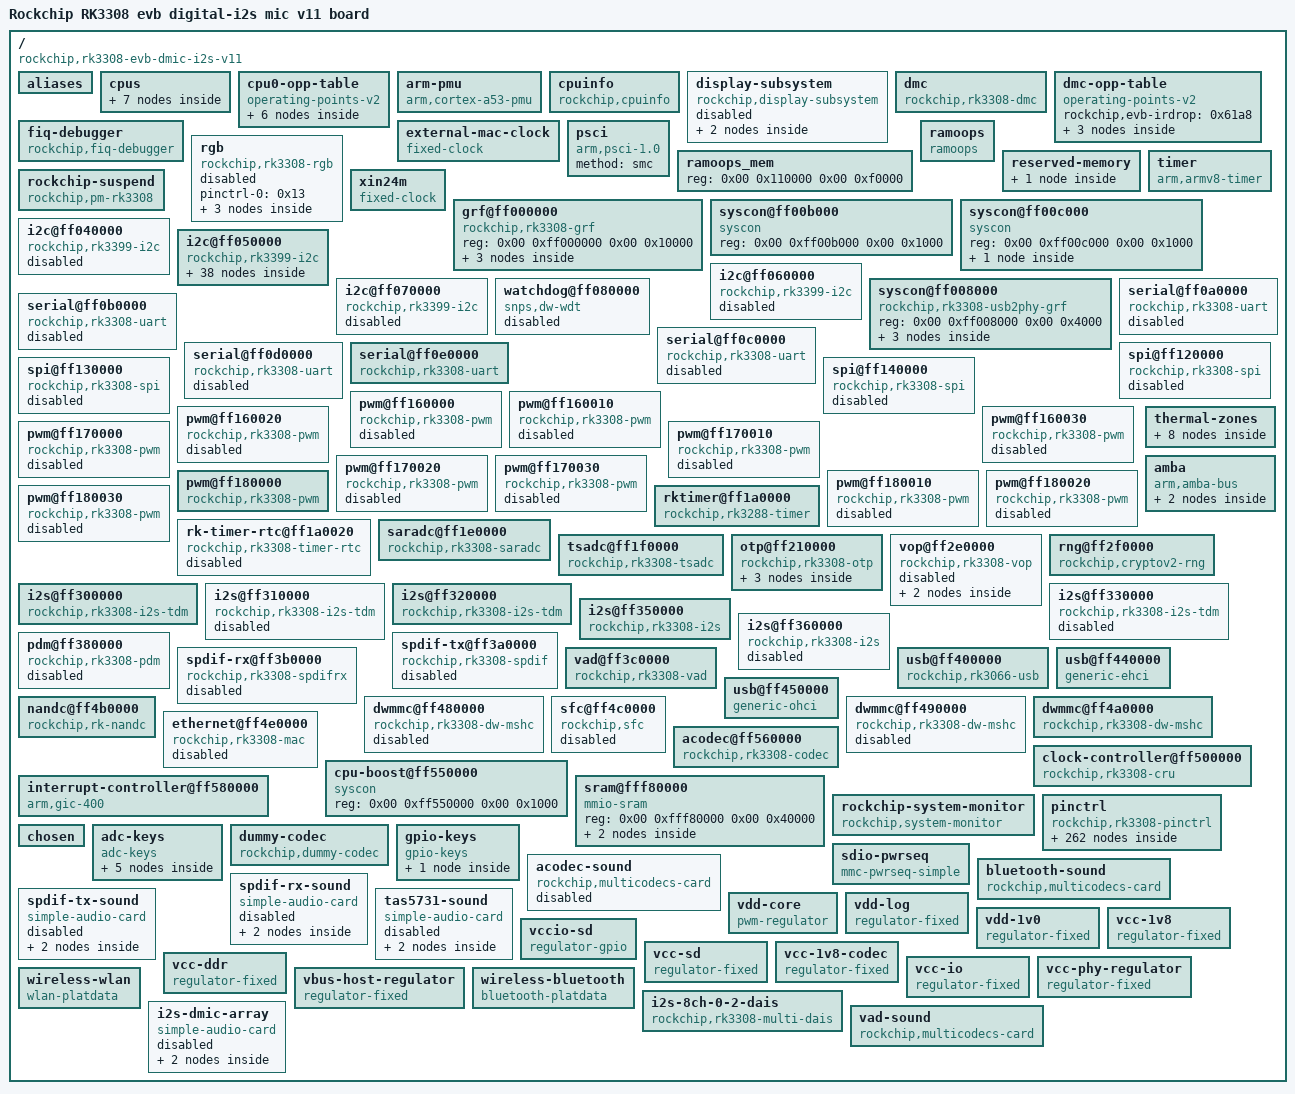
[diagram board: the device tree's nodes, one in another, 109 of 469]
/dts-v1/;

/ {
	compatible = "rockchip,rk3308-evb-dmic-i2s-v11\0rockchip,rk3308";
	interrupt-parent = <0x01>;
	#address-cells = <0x02>;
	#size-cells = <0x02>;
	model = "Rockchip RK3308 evb digital-i2s mic v11 board";

	aliases {
		ethernet0 = "/ethernet@ff4e0000";
		i2c0 = "/i2c@ff040000";
		i2c1 = "/i2c@ff050000";
		i2c2 = "/i2c@ff060000";
		i2c3 = "/i2c@ff070000";
		serial0 = "/serial@ff0a0000";
		serial1 = "/serial@ff0b0000";
		serial2 = "/serial@ff0c0000";
		serial3 = "/serial@ff0d0000";
		serial4 = "/serial@ff0e0000";
		spi0 = "/spi@ff120000";
		spi1 = "/spi@ff130000";
		spi2 = "/spi@ff140000";
	};

	cpus {
		#address-cells = <0x02>;
		#size-cells = <0x00>;

		cpu@0 {
			device_type = "cpu";
			compatible = "arm,cortex-a35\0arm,armv8";
			reg = <0x00 0x00>;
			enable-method = "psci";
			clocks = <0x02 0x05>;
			#cooling-cells = <0x02>;
			dynamic-power-coefficient = <0x5a>;
			operating-points-v2 = <0x03>;
			cpu-idle-states = <0x04>;
			next-level-cache = <0x05>;
			cpu-supply = <0x06>;
			phandle = <0x08>;
		};

		cpu@1 {
			device_type = "cpu";
			compatible = "arm,cortex-a35\0arm,armv8";
			reg = <0x00 0x01>;
			enable-method = "psci";
			operating-points-v2 = <0x03>;
			cpu-idle-states = <0x04>;
			next-level-cache = <0x05>;
			phandle = <0x09>;
		};

		cpu@2 {
			device_type = "cpu";
			compatible = "arm,cortex-a35\0arm,armv8";
			reg = <0x00 0x02>;
			enable-method = "psci";
			operating-points-v2 = <0x03>;
			cpu-idle-states = <0x04>;
			next-level-cache = <0x05>;
			phandle = <0x0a>;
		};

		cpu@3 {
			device_type = "cpu";
			compatible = "arm,cortex-a35\0arm,armv8";
			reg = <0x00 0x03>;
			enable-method = "psci";
			operating-points-v2 = <0x03>;
			cpu-idle-states = <0x04>;
			next-level-cache = <0x05>;
			phandle = <0x0b>;
		};

		idle-states {
			entry-method = "psci";

			cpu-sleep {
				compatible = "arm,idle-state";
				local-timer-stop;
				arm,psci-suspend-param = <0x10000>;
				entry-latency-us = <0x78>;
				exit-latency-us = <0xfa>;
				min-residency-us = <0x384>;
				phandle = <0x04>;
			};
		};

		l2-cache {
			compatible = "cache";
			phandle = <0x05>;
		};
	};

	cpu0-opp-table {
		compatible = "operating-points-v2";
		opp-shared;
		rockchip,temp-hysteresis = <0x1388>;
		rockchip,low-temp = <0x00>;
		rockchip,low-temp-min-volt = <0xf4240>;
		rockchip,max-volt = <0x147260>;
		rockchip,low-temp-adjust-volt = <0x00 0x510 0xc350>;
		rockchip,evb-irdrop = <0x61a8>;
		nvmem-cells = <0x07>;
		nvmem-cell-names = "leakage";
		rockchip,pvtm-voltage-sel = <0x00 0xd2f0 0x00 0xd2f1 0xdac0 0x01 0xdac1 0xe484 0x02 0xe485 0xee48 0x03 0xee49 0xf80c 0x04 0xf80d 0x1869f 0x05>;
		rockchip,pvtm-freq = <0x639c0>;
		rockchip,pvtm-volt = <0xfa3e8>;
		rockchip,pvtm-ch = <0x00 0x00>;
		rockchip,pvtm-sample-time = <0x3e8>;
		rockchip,pvtm-number = <0x0a>;
		rockchip,pvtm-error = <0x3e8>;
		rockchip,pvtm-ref-temp = <0x23>;
		rockchip,pvtm-temp-prop = <0xfffffff1 0xffffffdb>;
		rockchip,thermal-zone = "soc-thermal";
		phandle = <0x03>;

		opp-408000000 {
			opp-hz = <0x00 0x18519600>;
			opp-microvolt = <0xe7ef0 0xe7ef0 0x147260>;
			clock-latency-ns = <0x9c40>;
			opp-suspend;
		};

		opp-600000000 {
			opp-hz = <0x00 0x23c34600>;
			opp-microvolt = <0xe7ef0 0xe7ef0 0x147260>;
			clock-latency-ns = <0x9c40>;
		};

		opp-816000000 {
			opp-hz = <0x00 0x30a32c00>;
			opp-microvolt = <0xfa3e8 0xfa3e8 0x147260>;
			opp-microvolt-L0 = <0xfa3e8 0xfa3e8 0x147260>;
			opp-microvolt-L1 = <0xfa3e8 0xfa3e8 0x147260>;
			opp-microvolt-L2 = <0xfa3e8 0xfa3e8 0x147260>;
			opp-microvolt-L3 = <0xf4240 0xf4240 0x147260>;
			opp-microvolt-L4 = <0xee098 0xee098 0x147260>;
			opp-microvolt-L5 = <0xe7ef0 0xe7ef0 0x147260>;
			clock-latency-ns = <0x9c40>;
		};

		opp-1008000000 {
			opp-hz = <0x00 0x3c14dc00>;
			opp-microvolt = <0x112a88 0x112a88 0x147260>;
			opp-microvolt-L0 = <0x112a88 0x112a88 0x147260>;
			opp-microvolt-L1 = <0x10c8e0 0x10c8e0 0x147260>;
			opp-microvolt-L2 = <0x10c8e0 0x10c8e0 0x147260>;
			opp-microvolt-L3 = <0x106738 0x106738 0x147260>;
			opp-microvolt-L4 = <0x100590 0x100590 0x147260>;
			opp-microvolt-L5 = <0xfa3e8 0xfa3e8 0x147260>;
			clock-latency-ns = <0x9c40>;
		};

		opp-1200000000 {
			opp-hz = <0x00 0x47868c00>;
			opp-microvolt = <0x1312d0 0x1312d0 0x147260>;
			opp-microvolt-L0 = <0x1312d0 0x1312d0 0x147260>;
			opp-microvolt-L1 = <0x12b128 0x12b128 0x147260>;
			opp-microvolt-L2 = <0x124f80 0x124f80 0x147260>;
			opp-microvolt-L3 = <0x11edd8 0x11edd8 0x147260>;
			opp-microvolt-L4 = <0x118c30 0x118c30 0x147260>;
			opp-microvolt-L5 = <0x112a88 0x112a88 0x147260>;
			clock-latency-ns = <0x9c40>;
			status = "okay";
		};

		opp-1296000000 {
			opp-hz = <0x00 0x4d3f6400>;
			opp-microvolt = <0x13d620 0x13d620 0x147260>;
			opp-microvolt-L0 = <0x13d620 0x13d620 0x147260>;
			opp-microvolt-L1 = <0x137478 0x137478 0x147260>;
			opp-microvolt-L2 = <0x1312d0 0x1312d0 0x147260>;
			opp-microvolt-L3 = <0x12b128 0x12b128 0x147260>;
			opp-microvolt-L4 = <0x124f80 0x124f80 0x147260>;
			opp-microvolt-L5 = <0x11edd8 0x11edd8 0x147260>;
			clock-latency-ns = <0x9c40>;
			status = "okay";
		};
	};

	arm-pmu {
		compatible = "arm,cortex-a53-pmu";
		interrupts = <0x00 0x53 0x04 0x00 0x54 0x04 0x00 0x55 0x04 0x00 0x56 0x04>;
		interrupt-affinity = <0x08 0x09 0x0a 0x0b>;
	};

	cpuinfo {
		compatible = "rockchip,cpuinfo";
		nvmem-cells = <0x0c>;
		nvmem-cell-names = "id";
	};

	display-subsystem {
		compatible = "rockchip,display-subsystem";
		ports = <0x0d>;
		logo-memory-region = <0x0e>;
		status = "disabled";
		phandle = <0x9f>;

		route {

			route-rgb {
				status = "disabled";
				logo,uboot = "logo.bmp";
				logo,mode = "center";
				charge_logo,mode = "center";
				connect = <0x0f>;
				phandle = <0xa0>;
			};
		};
	};

	dmc {
		compatible = "rockchip,rk3308-dmc";
		clocks = <0x02 0x46>;
		clock-names = "dmc_clk";
		operating-points-v2 = <0x10>;
		status = "okay";
		center-supply = <0x11>;
		phandle = <0xa1>;
	};

	dmc-opp-table {
		compatible = "operating-points-v2";
		rockchip,evb-irdrop = <0x61a8>;
		phandle = <0x10>;

		opp-394000000 {
			opp-hz = <0x00 0x177bf680>;
			opp-microvolt = <0xe7ef0>;
		};

		opp-452000000 {
			opp-hz = <0x00 0x1af0f900>;
			opp-microvolt = <0xee098>;
		};

		opp-590000000 {
			opp-hz = <0x00 0x232aaf80>;
			opp-microvolt = <0xf4240>;
		};
	};

	fiq-debugger {
		compatible = "rockchip,fiq-debugger";
		rockchip,serial-id = <0x02>;
		rockchip,wake-irq = <0x00>;
		rockchip,irq-mode-enable = <0x00>;
		rockchip,baudrate = <0x16e360>;
		interrupts = <0x00 0x74 0x04>;
		status = "okay";
		phandle = <0xa2>;
	};

	external-mac-clock {
		compatible = "fixed-clock";
		clock-frequency = <0x2faf080>;
		clock-output-names = "mac_clkin";
		#clock-cells = <0x00>;
		phandle = <0x7e>;
	};

	psci {
		compatible = "arm,psci-1.0";
		method = "smc";
	};

	ramoops_mem {
		reg = <0x00 0x110000 0x00 0xf0000>;
		reg-names = "ramoops_mem";
		phandle = <0x12>;
	};

	ramoops {
		compatible = "ramoops";
		record-size = <0x00 0x30000>;
		console-size = <0x00 0xc0000>;
		ftrace-size = <0x00 0x00>;
		pmsg-size = <0x00 0x00>;
		memory-region = <0x12>;
		phandle = <0xa3>;
	};

	rgb {
		compatible = "rockchip,rk3308-rgb";
		status = "disabled";
		pinctrl-names = "default";
		pinctrl-0 = <0x13>;
		phandle = <0xa4>;

		ports {
			#address-cells = <0x01>;
			#size-cells = <0x00>;

			port@0 {
				reg = <0x00>;
				#address-cells = <0x01>;
				#size-cells = <0x00>;

				endpoint@0 {
					reg = <0x00>;
					remote-endpoint = <0x0f>;
					phandle = <0x52>;
				};
			};
		};
	};

	reserved-memory {
		#address-cells = <0x02>;
		#size-cells = <0x02>;
		ranges;

		drm-logo@00000000 {
			compatible = "rockchip,drm-logo";
			reg = <0x00 0x00 0x00 0x00>;
			phandle = <0x0e>;
		};
	};

	rockchip-suspend {
		compatible = "rockchip,pm-rk3308";
		status = "okay";
		rockchip,sleep-mode-config = <0x8000008>;
		rockchip,wakeup-config = <0x40000>;
		rockchip,pwm-regulator-config = <0x04>;
		phandle = <0xa5>;
	};

	timer {
		compatible = "arm,armv8-timer";
		interrupts = <0x01 0x0d 0xf04 0x01 0x0e 0xf04 0x01 0x0b 0xf04 0x01 0x0a 0xf04>;
	};

	xin24m {
		compatible = "fixed-clock";
		#clock-cells = <0x00>;
		clock-frequency = <0x16e3600>;
		clock-output-names = "xin24m";
		phandle = <0xa6>;
	};

	grf@ff000000 {
		compatible = "rockchip,rk3308-grf\0syscon\0simple-mfd";
		reg = <0x00 0xff000000 0x00 0x10000>;
		phandle = <0x4f>;

		io-domains {
			compatible = "rockchip,rk3308-io-voltage-domain";
			status = "okay";
			vccio0-supply = <0x14>;
			vccio1-supply = <0x14>;
			vccio2-supply = <0x15>;
			vccio3-supply = <0x14>;
			vccio4-supply = <0x15>;
			vccio5-supply = <0x16>;
			phandle = <0xa7>;
		};

		pmu-pvtm {
			compatible = "rockchip,rk3308-pmu-pvtm";
			clocks = <0x02 0x4a>;
			clock-names = "pmu";
			phandle = <0xa8>;
		};

		reboot-mode {
			compatible = "syscon-reboot-mode";
			offset = <0x500>;
			mode-bootloader = <0x5242c301>;
			mode-loader = <0x5242c301>;
			mode-normal = <0x5242c300>;
			mode-recovery = <0x5242c303>;
			mode-fastboot = <0x5242c309>;
			mode-panic = <0x5242c307>;
			mode-watchdog = <0x5242c308>;
		};
	};

	syscon@ff00b000 {
		compatible = "syscon\0simple-mfd";
		reg = <0x00 0xff00b000 0x00 0x1000>;
		#address-cells = <0x01>;
		#size-cells = <0x01>;
		phandle = <0x80>;
	};

	syscon@ff00c000 {
		compatible = "syscon\0simple-mfd";
		reg = <0x00 0xff00c000 0x00 0x1000>;
		#address-cells = <0x01>;
		#size-cells = <0x01>;
		phandle = <0xa9>;

		pvtm {
			compatible = "rockchip,rk3308-pvtm";
			clocks = <0x02 0x10>;
			clock-names = "core";
			phandle = <0xaa>;
		};
	};

	i2c@ff040000 {
		compatible = "rockchip,rk3399-i2c";
		reg = <0x00 0xff040000 0x00 0x1000>;
		clocks = <0x02 0x16 0x02 0xca>;
		clock-names = "i2c\0pclk";
		interrupts = <0x00 0x0b 0x04>;
		pinctrl-names = "default";
		pinctrl-0 = <0x17>;
		#address-cells = <0x01>;
		#size-cells = <0x00>;
		status = "disabled";
		phandle = <0xab>;
	};

	i2c@ff050000 {
		compatible = "rockchip,rk3399-i2c";
		reg = <0x00 0xff050000 0x00 0x1000>;
		clocks = <0x02 0x17 0x02 0xcb>;
		clock-names = "i2c\0pclk";
		interrupts = <0x00 0x0c 0x04>;
		pinctrl-names = "default";
		pinctrl-0 = <0x18>;
		#address-cells = <0x01>;
		#size-cells = <0x00>;
		status = "okay";
		clock-frequency = <0x61a80>;
		phandle = <0xac>;

		tas5731@1a {
			#sound-dai-cells = <0x00>;
			compatible = "ti,tas5731";
			reg = <0x1a>;
			clocks = <0x02 0x51>;
			clock-names = "mclk";
			pinctrl-names = "default";
			pinctrl-0 = <0x19>;
			pdn-gpios = <0x1a 0x05 0x01>;
			reset-gpios = <0x1b 0x01 0x01>;
			phandle = <0x96>;
		};

		led-controller@3c {
			compatible = "issi,is31fl3236";
			reg = <0x3c>;
			#address-cells = <0x01>;
			#size-cells = <0x00>;
			reset-gpios = <0x1a 0x08 0x00>;
			status = "okay";
			phandle = <0xad>;

			led@1 {
				label = "led1";
				reg = <0x01>;
				led-max-microamp = <0x2710>;
				linux,default-trigger = "timer";
				linux,default-trigger-delay-ms = <0x00>;
				linux,blink-delay-on-ms = <0x64>;
				linux,blink-delay-off-ms = <0x4b0>;
				phandle = <0xae>;
			};

			led@2 {
				label = "led2";
				reg = <0x02>;
				led-max-microamp = <0x2710>;
				linux,default-trigger = "timer";
				linux,default-trigger-delay-ms = <0x00>;
				linux,blink-delay-on-ms = <0x64>;
				linux,blink-delay-off-ms = <0x4b0>;
				phandle = <0xaf>;
			};

			led@3 {
				label = "led3";
				reg = <0x03>;
				led-max-microamp = <0x2710>;
				linux,default-trigger = "default-on";
				phandle = <0xb0>;
			};

			led@4 {
				label = "led4";
				reg = <0x04>;
				led-max-microamp = <0x2710>;
				linux,default-trigger = "timer";
				linux,default-trigger-delay-ms = <0x64>;
				linux,blink-delay-on-ms = <0x64>;
				linux,blink-delay-off-ms = <0x4b0>;
				phandle = <0xb1>;
			};

			led@5 {
				label = "led5";
				reg = <0x05>;
				led-max-microamp = <0x2710>;
				linux,default-trigger = "timer";
				linux,default-trigger-delay-ms = <0x64>;
				linux,blink-delay-on-ms = <0x64>;
				linux,blink-delay-off-ms = <0x4b0>;
				phandle = <0xb2>;
			};

			led@6 {
				label = "led6";
				reg = <0x06>;
				led-max-microamp = <0x2710>;
				linux,default-trigger = "default-on";
				phandle = <0xb3>;
			};

			led@7 {
				label = "led7";
				reg = <0x07>;
				led-max-microamp = <0x2710>;
				linux,default-trigger = "timer";
				linux,default-trigger-delay-ms = <0xc8>;
				linux,blink-delay-on-ms = <0x64>;
				linux,blink-delay-off-ms = <0x4b0>;
				phandle = <0xb4>;
			};

			led@8 {
				label = "led8";
				reg = <0x08>;
				led-max-microamp = <0x2710>;
				linux,default-trigger = "timer";
				linux,default-trigger-delay-ms = <0xc8>;
				linux,blink-delay-on-ms = <0x64>;
				linux,blink-delay-off-ms = <0x4b0>;
				phandle = <0xb5>;
			};

			led@9 {
				label = "led9";
				reg = <0x09>;
				led-max-microamp = <0x2710>;
				linux,default-trigger = "default-on";
				phandle = <0xb6>;
			};

			led@10 {
				label = "led10";
				reg = <0x0a>;
				led-max-microamp = <0x2710>;
				linux,default-trigger = "timer";
				linux,default-trigger-delay-ms = <0x12c>;
				linux,blink-delay-on-ms = <0x64>;
				linux,blink-delay-off-ms = <0x4b0>;
				phandle = <0xb7>;
			};

			led@11 {
				label = "led11";
				reg = <0x0b>;
				led-max-microamp = <0x2710>;
				linux,default-trigger = "timer";
				linux,default-trigger-delay-ms = <0x12c>;
				linux,blink-delay-on-ms = <0x64>;
				linux,blink-delay-off-ms = <0x4b0>;
				phandle = <0xb8>;
			};

			led@12 {
				label = "led12";
				reg = <0x0c>;
				led-max-microamp = <0x2710>;
				linux,default-trigger = "default-on";
				phandle = <0xb9>;
			};

			led@13 {
				label = "led13";
				reg = <0x0d>;
				led-max-microamp = <0x2710>;
				linux,default-trigger = "timer";
				linux,default-trigger-delay-ms = <0x190>;
				linux,blink-delay-on-ms = <0x64>;
				linux,blink-delay-off-ms = <0x4b0>;
				phandle = <0xba>;
			};

			led@14 {
				label = "led14";
				reg = <0x0e>;
				led-max-microamp = <0x2710>;
				linux,default-trigger = "timer";
				linux,default-trigger-delay-ms = <0x190>;
				linux,blink-delay-on-ms = <0x64>;
				linux,blink-delay-off-ms = <0x4b0>;
				phandle = <0xbb>;
			};

			led@15 {
				label = "led15";
				reg = <0x0f>;
				led-max-microamp = <0x2710>;
				linux,default-trigger = "default-on";
				phandle = <0xbc>;
			};

			led@16 {
				label = "led16";
				reg = <0x10>;
				led-max-microamp = <0x2710>;
				linux,default-trigger = "timer";
				linux,default-trigger-delay-ms = <0x1f4>;
				linux,blink-delay-on-ms = <0x64>;
				linux,blink-delay-off-ms = <0x4b0>;
				phandle = <0xbd>;
			};

			led@17 {
				label = "led17";
				reg = <0x11>;
				led-max-microamp = <0x2710>;
				linux,default-trigger = "timer";
				linux,default-trigger-delay-ms = <0x1f4>;
				linux,blink-delay-on-ms = <0x64>;
				linux,blink-delay-off-ms = <0x4b0>;
				phandle = <0xbe>;
			};

			led@18 {
				label = "led18";
				reg = <0x12>;
				led-max-microamp = <0x2710>;
				linux,default-trigger = "default-on";
				phandle = <0xbf>;
			};

			led@19 {
				label = "led19";
				reg = <0x13>;
				led-max-microamp = <0x2710>;
				linux,default-trigger = "timer";
				linux,default-trigger-delay-ms = <0x258>;
				linux,blink-delay-on-ms = <0x64>;
				linux,blink-delay-off-ms = <0x4b0>;
				phandle = <0xc0>;
			};

			led@20 {
				label = "led20";
				reg = <0x14>;
				led-max-microamp = <0x2710>;
				linux,default-trigger = "timer";
				linux,default-trigger-delay-ms = <0x258>;
				linux,blink-delay-on-ms = <0x64>;
				linux,blink-delay-off-ms = <0x4b0>;
				phandle = <0xc1>;
			};

			led@21 {
				label = "led21";
				reg = <0x15>;
				led-max-microamp = <0x2710>;
				linux,default-trigger = "default-on";
				phandle = <0xc2>;
			};

			led@22 {
				label = "led22";
				reg = <0x16>;
				led-max-microamp = <0x2710>;
				linux,default-trigger = "timer";
				linux,default-trigger-delay-ms = <0x2bc>;
				linux,blink-delay-on-ms = <0x64>;
				linux,blink-delay-off-ms = <0x4b0>;
				phandle = <0xc3>;
			};

			led@23 {
				label = "led23";
				reg = <0x17>;
				led-max-microamp = <0x2710>;
				linux,default-trigger = "timer";
				linux,default-trigger-delay-ms = <0x2bc>;
				linux,blink-delay-on-ms = <0x64>;
				linux,blink-delay-off-ms = <0x4b0>;
				phandle = <0xc4>;
			};

			led@24 {
				label = "led24";
				reg = <0x18>;
				led-max-microamp = <0x2710>;
				linux,default-trigger = "default-on";
				phandle = <0xc5>;
			};

			led@25 {
				label = "led25";
				reg = <0x19>;
				led-max-microamp = <0x2710>;
				linux,default-trigger = "timer";
				linux,default-trigger-delay-ms = <0x320>;
				linux,blink-delay-on-ms = <0x64>;
				linux,blink-delay-off-ms = <0x4b0>;
				phandle = <0xc6>;
			};

			led@26 {
				label = "led26";
				reg = <0x1a>;
				led-max-microamp = <0x2710>;
				linux,default-trigger = "timer";
				linux,default-trigger-delay-ms = <0x320>;
				linux,blink-delay-on-ms = <0x64>;
				linux,blink-delay-off-ms = <0x4b0>;
				phandle = <0xc7>;
			};

			led@27 {
				label = "led27";
				reg = <0x1b>;
				led-max-microamp = <0x2710>;
				linux,default-trigger = "default-on";
				phandle = <0xc8>;
			};

			led@28 {
				label = "led28";
				reg = <0x1c>;
				led-max-microamp = <0x2710>;
				linux,default-trigger = "timer";
				linux,default-trigger-delay-ms = <0x384>;
				linux,blink-delay-on-ms = <0x64>;
				linux,blink-delay-off-ms = <0x4b0>;
				phandle = <0xc9>;
			};

			led@29 {
				label = "led29";
				reg = <0x1d>;
				led-max-microamp = <0x2710>;
				linux,default-trigger = "timer";
				linux,default-trigger-delay-ms = <0x384>;
				linux,blink-delay-on-ms = <0x64>;
				linux,blink-delay-off-ms = <0x4b0>;
				phandle = <0xca>;
			};

			led@30 {
				label = "led30";
				reg = <0x1e>;
				led-max-microamp = <0x2710>;
				linux,default-trigger = "default-on";
				phandle = <0xcb>;
			};

			led@31 {
				label = "led31";
				reg = <0x1f>;
				led-max-microamp = <0x2710>;
				linux,default-trigger = "timer";
				linux,default-trigger-delay-ms = <0x3e8>;
				linux,blink-delay-on-ms = <0x64>;
				linux,blink-delay-off-ms = <0x4b0>;
				phandle = <0xcc>;
			};

			led@32 {
				label = "led32";
				reg = <0x20>;
				led-max-microamp = <0x2710>;
				linux,default-trigger = "timer";
				linux,default-trigger-delay-ms = <0x3e8>;
				linux,blink-delay-on-ms = <0x64>;
				linux,blink-delay-off-ms = <0x4b0>;
				phandle = <0xcd>;
			};

			led@33 {
				label = "led33";
				reg = <0x21>;
				led-max-microamp = <0x2710>;
				linux,default-trigger = "default-on";
				phandle = <0xce>;
			};

			led@34 {
				label = "led34";
				reg = <0x22>;
				led-max-microamp = <0x2710>;
				linux,default-trigger = "timer";
				linux,default-trigger-delay-ms = <0x44c>;
				linux,blink-delay-on-ms = <0x64>;
				linux,blink-delay-off-ms = <0x4b0>;
				phandle = <0xcf>;
			};

			led@35 {
				label = "led35";
				reg = <0x23>;
				led-max-microamp = <0x2710>;
				linux,default-trigger = "timer";
				linux,default-trigger-delay-ms = <0x44c>;
				linux,blink-delay-on-ms = <0x64>;
				linux,blink-delay-off-ms = <0x4b0>;
				phandle = <0xd0>;
			};

			led@36 {
				label = "led36";
				reg = <0x24>;
				led-max-microamp = <0x2710>;
				linux,default-trigger = "default-on";
				phandle = <0xd1>;
			};
		};
	};

	i2c@ff060000 {
		compatible = "rockchip,rk3399-i2c";
		reg = <0x00 0xff060000 0x00 0x1000>;
		clocks = <0x02 0x18 0x02 0xcc>;
		clock-names = "i2c\0pclk";
		interrupts = <0x00 0x0d 0x04>;
		pinctrl-names = "default";
		pinctrl-0 = <0x1c>;
		#address-cells = <0x01>;
		#size-cells = <0x00>;
		status = "disabled";
		phandle = <0xd2>;
	};

	i2c@ff070000 {
		compatible = "rockchip,rk3399-i2c";
		reg = <0x00 0xff070000 0x00 0x1000>;
		clocks = <0x02 0x19 0x02 0xcd>;
		clock-names = "i2c\0pclk";
		interrupts = <0x00 0x0e 0x04>;
		pinctrl-names = "default";
		pinctrl-0 = <0x1d>;
		#address-cells = <0x01>;
		#size-cells = <0x00>;
		status = "disabled";
		phandle = <0xd3>;
	};

	syscon@ff008000 {
		compatible = "rockchip,rk3308-usb2phy-grf\0syscon\0simple-mfd";
		reg = <0x00 0xff008000 0x00 0x4000>;
		#address-cells = <0x01>;
		#size-cells = <0x01>;
		phandle = <0xd4>;

		usb2-phy@100 {
			compatible = "rockchip,rk3308-usb2phy";
			reg = <0x100 0x10>;
			clocks = <0x02 0x48>;
			clock-names = "phyclk";
			#clock-cells = <0x00>;
			assigned-clocks = <0x02 0x0e>;
			assigned-clock-parents = <0x1e>;
			clock-output-names = "usb480m_phy";
			status = "okay";
			phandle = <0x1e>;

			otg-port {
				#phy-cells = <0x00>;
				interrupts = <0x00 0x43 0x04 0x00 0x44 0x04 0x00 0x45 0x04>;
				interrupt-names = "otg-bvalid\0otg-id\0linestate";
				status = "okay";
				phandle = <0x70>;
			};

			host-port {
				#phy-cells = <0x00>;
				interrupts = <0x00 0x4a 0x04>;
				interrupt-names = "linestate";
				status = "okay";
				phy-supply = <0x1f>;
				phandle = <0x71>;
			};
		};
	};

	watchdog@ff080000 {
		compatible = "snps,dw-wdt";
		reg = <0x00 0xff080000 0x00 0x100>;
		clocks = <0x02 0xd6>;
		interrupts = <0x00 0x0a 0x04>;
		status = "disabled";
		phandle = <0xd5>;
	};

	serial@ff0a0000 {
		compatible = "rockchip,rk3308-uart\0snps,dw-apb-uart";
		reg = <0x00 0xff0a0000 0x00 0x100>;
		interrupts = <0x00 0x12 0x04>;
		clocks = <0x02 0x11 0x02 0xc5>;
		clock-names = "baudclk\0apb_pclk";
		reg-shift = <0x02>;
		reg-io-width = <0x04>;
		dmas = <0x20 0x04 0x20 0x05>;
		dma-names = "tx\0rx";
		pinctrl-names = "default";
		pinctrl-0 = <0x21 0x22 0x23>;
		status = "disabled";
		phandle = <0xd6>;
	};

	serial@ff0b0000 {
		compatible = "rockchip,rk3308-uart\0snps,dw-apb-uart";
		reg = <0x00 0xff0b0000 0x00 0x100>;
		interrupts = <0x00 0x13 0x04>;
		clocks = <0x02 0x12 0x02 0xc6>;
		clock-names = "baudclk\0apb_pclk";
		reg-shift = <0x02>;
		reg-io-width = <0x04>;
		dmas = <0x20 0x06 0x20 0x07>;
		dma-names = "tx\0rx";
		pinctrl-names = "default";
		pinctrl-0 = <0x24 0x25 0x26>;
		status = "disabled";
		phandle = <0xd7>;
	};

	serial@ff0c0000 {
		compatible = "rockchip,rk3308-uart\0snps,dw-apb-uart";
		reg = <0x00 0xff0c0000 0x00 0x100>;
		interrupts = <0x00 0x14 0x04>;
		clocks = <0x02 0x13 0x02 0xc7>;
		clock-names = "baudclk\0apb_pclk";
		reg-shift = <0x02>;
		reg-io-width = <0x04>;
		dmas = <0x20 0x08 0x20 0x09>;
		dma-names = "tx\0rx";
		pinctrl-names = "default";
		pinctrl-0 = <0x27>;
		status = "disabled";
		phandle = <0xd8>;
	};

	serial@ff0d0000 {
		compatible = "rockchip,rk3308-uart\0snps,dw-apb-uart";
		reg = <0x00 0xff0d0000 0x00 0x100>;
		interrupts = <0x00 0x15 0x04>;
		clocks = <0x02 0x14 0x02 0xc8>;
		clock-names = "baudclk\0apb_pclk";
		reg-shift = <0x02>;
		reg-io-width = <0x04>;
		dmas = <0x20 0x0a 0x20 0x0b>;
		dma-names = "tx\0rx";
		pinctrl-names = "default";
		pinctrl-0 = <0x28>;
		status = "disabled";
		phandle = <0xd9>;
	};

	serial@ff0e0000 {
		compatible = "rockchip,rk3308-uart\0snps,dw-apb-uart";
		reg = <0x00 0xff0e0000 0x00 0x100>;
		interrupts = <0x00 0x16 0x04>;
		clocks = <0x02 0x15 0x02 0xc9>;
		clock-names = "baudclk\0apb_pclk";
		reg-shift = <0x02>;
		reg-io-width = <0x04>;
		dmas = <0x29 0x12 0x29 0x13>;
		dma-names = "tx\0rx";
		pinctrl-names = "default";
		pinctrl-0 = <0x2a 0x2b>;
		status = "okay";
		phandle = <0xda>;
	};

	spi@ff120000 {
		compatible = "rockchip,rk3308-spi\0rockchip,rk3066-spi";
		reg = <0x00 0xff120000 0x00 0x1000>;
		interrupts = <0x00 0x0f 0x04>;
		#address-cells = <0x01>;
		#size-cells = <0x00>;
		clocks = <0x02 0x1b 0x02 0xcf>;
		clock-names = "spiclk\0apb_pclk";
		dmas = <0x20 0x00 0x20 0x01>;
		dma-names = "tx\0rx";
		pinctrl-names = "default\0high_speed";
		pinctrl-0 = <0x2c 0x2d 0x2e 0x2f>;
		pinctrl-1 = <0x30 0x2d 0x31 0x32>;
		status = "disabled";
		phandle = <0xdb>;
	};

	spi@ff130000 {
		compatible = "rockchip,rk3308-spi\0rockchip,rk3066-spi";
		reg = <0x00 0xff130000 0x00 0x1000>;
		interrupts = <0x00 0x10 0x04>;
		#address-cells = <0x01>;
		#size-cells = <0x00>;
		clocks = <0x02 0x1c 0x02 0xd0>;
		clock-names = "spiclk\0apb_pclk";
		dmas = <0x20 0x02 0x20 0x03>;
		dma-names = "tx\0rx";
		pinctrl-names = "default\0high_speed";
		pinctrl-0 = <0x33 0x34 0x35 0x36>;
		pinctrl-1 = <0x37 0x34 0x38 0x39>;
		status = "disabled";
		phandle = <0xdc>;
	};

	spi@ff140000 {
		compatible = "rockchip,rk3308-spi\0rockchip,rk3066-spi";
		reg = <0x00 0xff140000 0x00 0x1000>;
		interrupts = <0x00 0x11 0x04>;
		#address-cells = <0x01>;
		#size-cells = <0x00>;
		clocks = <0x02 0x1d 0x02 0xd1>;
		clock-names = "spiclk\0apb_pclk";
		dmas = <0x29 0x10 0x29 0x11>;
		dma-names = "tx\0rx";
		pinctrl-names = "default\0high_speed";
		pinctrl-0 = <0x3a 0x3b 0x3c 0x3d>;
		pinctrl-1 = <0x3e 0x3b 0x3f 0x40>;
		status = "disabled";
		phandle = <0xdd>;
	};

	pwm@ff160000 {
		compatible = "rockchip,rk3308-pwm\0rockchip,rk3328-pwm";
		reg = <0x00 0xff160000 0x00 0x10>;
		#pwm-cells = <0x03>;
		pinctrl-names = "active";
		pinctrl-0 = <0x41>;
		clocks = <0x02 0x79 0x02 0xe8>;
		clock-names = "pwm\0pclk";
		status = "disabled";
		phandle = <0xde>;
	};

	pwm@ff160010 {
		compatible = "rockchip,rk3308-pwm\0rockchip,rk3328-pwm";
		reg = <0x00 0xff160010 0x00 0x10>;
		#pwm-cells = <0x03>;
		pinctrl-names = "active";
		pinctrl-0 = <0x42>;
		clocks = <0x02 0x79 0x02 0xe8>;
		clock-names = "pwm\0pclk";
		status = "disabled";
		phandle = <0xdf>;
	};

	pwm@ff160020 {
		compatible = "rockchip,rk3308-pwm\0rockchip,rk3328-pwm";
		reg = <0x00 0xff160020 0x00 0x10>;
		#pwm-cells = <0x03>;
		pinctrl-names = "active";
		pinctrl-0 = <0x43>;
		clocks = <0x02 0x79 0x02 0xe8>;
		clock-names = "pwm\0pclk";
		status = "disabled";
		phandle = <0xe0>;
	};

	pwm@ff160030 {
		compatible = "rockchip,rk3308-pwm\0rockchip,rk3328-pwm";
		reg = <0x00 0xff160030 0x00 0x10>;
		#pwm-cells = <0x03>;
		pinctrl-names = "active";
		pinctrl-0 = <0x44>;
		clocks = <0x02 0x79 0x02 0xe8>;
		clock-names = "pwm\0pclk";
		status = "disabled";
		phandle = <0xe1>;
	};

	pwm@ff170000 {
		compatible = "rockchip,rk3308-pwm\0rockchip,rk3328-pwm";
		reg = <0x00 0xff170000 0x00 0x10>;
		#pwm-cells = <0x03>;
		pinctrl-names = "active";
		pinctrl-0 = <0x45>;
		clocks = <0x02 0x78 0x02 0xe7>;
		clock-names = "pwm\0pclk";
		status = "disabled";
		phandle = <0xe2>;
	};

	pwm@ff170010 {
		compatible = "rockchip,rk3308-pwm\0rockchip,rk3328-pwm";
		reg = <0x00 0xff170010 0x00 0x10>;
		#pwm-cells = <0x03>;
		pinctrl-names = "active";
		pinctrl-0 = <0x46>;
		clocks = <0x02 0x78 0x02 0xe7>;
		clock-names = "pwm\0pclk";
		status = "disabled";
		phandle = <0xe3>;
	};

	pwm@ff170020 {
		compatible = "rockchip,rk3308-pwm\0rockchip,rk3328-pwm";
		reg = <0x00 0xff170020 0x00 0x10>;
		#pwm-cells = <0x03>;
		pinctrl-names = "active";
		pinctrl-0 = <0x47>;
		clocks = <0x02 0x78 0x02 0xe7>;
		clock-names = "pwm\0pclk";
		status = "disabled";
		phandle = <0xe4>;
	};

	pwm@ff170030 {
		compatible = "rockchip,rk3308-pwm\0rockchip,rk3328-pwm";
		reg = <0x00 0xff170030 0x00 0x10>;
		#pwm-cells = <0x03>;
		pinctrl-names = "active";
		pinctrl-0 = <0x48>;
		clocks = <0x02 0x78 0x02 0xe7>;
		clock-names = "pwm\0pclk";
		status = "disabled";
		phandle = <0xe5>;
	};

	pwm@ff180000 {
		compatible = "rockchip,rk3308-pwm\0rockchip,rk3328-pwm";
		reg = <0x00 0xff180000 0x00 0x10>;
		#pwm-cells = <0x03>;
		pinctrl-names = "active";
		pinctrl-0 = <0x49>;
		clocks = <0x02 0x1a 0x02 0xce>;
		clock-names = "pwm\0pclk";
		status = "okay";
		phandle = <0x97>;
	};

	pwm@ff180010 {
		compatible = "rockchip,rk3308-pwm\0rockchip,rk3328-pwm";
		reg = <0x00 0xff180010 0x00 0x10>;
		#pwm-cells = <0x03>;
		pinctrl-names = "active";
		pinctrl-0 = <0x4a>;
		clocks = <0x02 0x1a 0x02 0xce>;
		clock-names = "pwm\0pclk";
		status = "disabled";
		phandle = <0xe6>;
	};

	pwm@ff180020 {
		compatible = "rockchip,rk3308-pwm\0rockchip,rk3328-pwm";
		reg = <0x00 0xff180020 0x00 0x10>;
		#pwm-cells = <0x03>;
		pinctrl-names = "active";
		pinctrl-0 = <0x4b>;
		clocks = <0x02 0x1a 0x02 0xce>;
		clock-names = "pwm\0pclk";
		status = "disabled";
		phandle = <0xe7>;
	};

	pwm@ff180030 {
		compatible = "rockchip,rk3308-pwm\0rockchip,rk3328-pwm";
		reg = <0x00 0xff180030 0x00 0x10>;
		#pwm-cells = <0x03>;
		pinctrl-names = "active";
		pinctrl-0 = <0x4c>;
		clocks = <0x02 0x1a 0x02 0xce>;
		clock-names = "pwm\0pclk";
		status = "disabled";
		phandle = <0xe8>;
	};

	rktimer@ff1a0000 {
		compatible = "rockchip,rk3288-timer";
		reg = <0x00 0xff1a0000 0x00 0x20>;
		interrupts = <0x00 0x19 0x04>;
		clocks = <0x02 0xd4 0x02 0x1e>;
		clock-names = "pclk\0timer";
		phandle = <0xe9>;
	};

	rk-timer-rtc@ff1a0020 {
		compatible = "rockchip,rk3308-timer-rtc";
		reg = <0x00 0xff1a0020 0x00 0x20>;
		interrupts = <0x00 0x1a 0x04>;
		clocks = <0x02 0xd4 0x02 0x1f>;
		clock-names = "pclk\0timer";
		status = "disabled";
		phandle = <0xea>;
	};

	saradc@ff1e0000 {
		compatible = "rockchip,rk3308-saradc\0rockchip,rk3399-saradc";
		reg = <0x00 0xff1e0000 0x00 0x100>;
		interrupts = <0x00 0x25 0x04>;
		#io-channel-cells = <0x01>;
		clocks = <0x02 0x25 0x02 0xd2>;
		clock-names = "saradc\0apb_pclk";
		resets = <0x02 0x46>;
		reset-names = "saradc-apb";
		status = "okay";
		vref-supply = <0x15>;
		phandle = <0x8c>;
	};

	thermal-zones {
		phandle = <0xeb>;

		soc-thermal {
			polling-delay-passive = <0x14>;
			polling-delay = <0x3e8>;
			sustainable-power = <0x12c>;
			thermal-sensors = <0x4d 0x00>;
			phandle = <0xec>;

			trips {

				trip-point-0 {
					temperature = <0x11170>;
					hysteresis = <0x7d0>;
					type = "passive";
					phandle = <0xed>;
				};

				trip-point-1 {
					temperature = <0x14c08>;
					hysteresis = <0x7d0>;
					type = "passive";
					phandle = <0x4e>;
				};

				soc-crit {
					temperature = <0x1c138>;
					hysteresis = <0x7d0>;
					type = "critical";
					phandle = <0xee>;
				};
			};

			cooling-maps {

				map0 {
					trip = <0x4e>;
					cooling-device = <0x08 0xffffffff 0xffffffff>;
					contribution = <0x1000>;
				};
			};
		};

		logic-thermal {
			polling-delay-passive = <0x64>;
			polling-delay = <0x3e8>;
			thermal-sensors = <0x4d 0x01>;
			phandle = <0xef>;
		};
	};

	tsadc@ff1f0000 {
		compatible = "rockchip,rk3308-tsadc";
		reg = <0x00 0xff1f0000 0x00 0x100>;
		interrupts = <0x00 0x26 0x04>;
		rockchip,grf = <0x4f>;
		clocks = <0x02 0x24 0x02 0xd3>;
		clock-names = "tsadc\0apb_pclk";
		assigned-clocks = <0x02 0x24>;
		assigned-clock-rates = <0xc350>;
		resets = <0x02 0x48>;
		reset-names = "tsadc-apb";
		pinctrl-names = "gpio\0otpout";
		pinctrl-0 = <0x50>;
		pinctrl-1 = <0x51>;
		#thermal-sensor-cells = <0x01>;
		rockchip,hw-tshut-temp = <0x1d4c0>;
		status = "okay";
		rockchip,hw-tshut-mode = <0x00>;
		rockchip,hw-tshut-polarity = <0x01>;
		phandle = <0x4d>;
	};

	otp@ff210000 {
		compatible = "rockchip,rk3308-otp";
		reg = <0x00 0xff210000 0x00 0x4000>;
		#address-cells = <0x01>;
		#size-cells = <0x01>;
		clocks = <0x02 0x27 0x02 0xd5 0x02 0xe5>;
		clock-names = "clk_otp\0pclk_otp\0pclk_otp_phy";
		resets = <0x02 0x54>;
		reset-names = "otp_phy";
		phandle = <0xf0>;

		id@7 {
			reg = <0x07 0x10>;
			phandle = <0x0c>;
		};

		cpu-leakage@17 {
			reg = <0x17 0x01>;
			phandle = <0x07>;
		};

		logic-leakage@18 {
			reg = <0x18 0x01>;
			phandle = <0xf1>;
		};
	};

	amba {
		compatible = "arm,amba-bus";
		#address-cells = <0x02>;
		#size-cells = <0x02>;
		ranges;

		dma-controller@ff2c0000 {
			compatible = "arm,pl330\0arm,primecell";
			reg = <0x00 0xff2c0000 0x00 0x4000>;
			interrupts = <0x00 0x00 0x04 0x00 0x01 0x04>;
			#dma-cells = <0x01>;
			clocks = <0x02 0x8a>;
			clock-names = "apb_pclk";
			peripherals-req-type-burst;
			phandle = <0x20>;
		};

		dma-controller@ff2d0000 {
			compatible = "arm,pl330\0arm,primecell";
			reg = <0x00 0xff2d0000 0x00 0x4000>;
			interrupts = <0x00 0x02 0x04 0x00 0x03 0x04>;
			#dma-cells = <0x01>;
			clocks = <0x02 0x8b>;
			clock-names = "apb_pclk";
			peripherals-req-type-burst;
			phandle = <0x29>;
		};
	};

	vop@ff2e0000 {
		compatible = "rockchip,rk3308-vop";
		reg = <0x00 0xff2e0000 0x00 0x1fc 0x00 0xff2e0a00 0x00 0x400>;
		reg-names = "regs\0gamma_lut";
		interrupts = <0x00 0x2e 0x04>;
		clocks = <0x02 0x88 0x02 0x7d 0x02 0xac>;
		clock-names = "aclk_vop\0dclk_vop\0hclk_vop";
		status = "disabled";
		phandle = <0xf2>;

		port {
			#address-cells = <0x01>;
			#size-cells = <0x00>;
			phandle = <0x0d>;

			endpoint@0 {
				reg = <0x00>;
				remote-endpoint = <0x52>;
				phandle = <0x0f>;
			};
		};
	};

	rng@ff2f0000 {
		compatible = "rockchip,cryptov2-rng";
		reg = <0x00 0xff2f0000 0x00 0x4000>;
		clocks = <0x02 0x29 0x02 0x2a 0x02 0x87 0x02 0xab>;
		clock-names = "clk_crypto\0clk_crypto_apk\0aclk_crypto\0hclk_crypto";
		assigned-clocks = <0x02 0x29 0x02 0x2a 0x02 0x87 0x02 0xab>;
		assigned-clock-rates = <0x8f0d180 0x8f0d180 0xbebc200 0x5f5e100>;
		resets = <0x02 0x24>;
		reset-names = "reset";
		status = "okay";
		phandle = <0xf3>;
	};

	i2s@ff300000 {
		compatible = "rockchip,rk3308-i2s-tdm";
		reg = <0x00 0xff300000 0x00 0x1000>;
		interrupts = <0x00 0x30 0x04>;
		clocks = <0x02 0x4c 0x02 0x4e 0x02 0xa4 0x02 0x6e 0x02 0x6f 0x02 0x03 0x02 0x04>;
		clock-names = "mclk_tx\0mclk_rx\0hclk\0mclk_tx_src\0mclk_rx_src\0mclk_root0\0mclk_root1";
		dmas = <0x29 0x00 0x29 0x01>;
		dma-names = "tx\0rx";
		resets = <0x02 0x89 0x02 0x8a>;
		reset-names = "tx-m\0rx-m";
		rockchip,cru = <0x02>;
		rockchip,grf = <0x4f>;
		rockchip,mclk-calibrate;
		pinctrl-names = "default";
		pinctrl-0 = <0x53 0x54 0x55 0x56 0x57 0x58 0x59 0x5a 0x5b 0x5c 0x5d 0x5e 0x5f>;
		status = "okay";
		rockchip,no-dmaengine;
		#sound-dai-cells = <0x00>;
		phandle = <0x6f>;
	};

	i2s@ff310000 {
		compatible = "rockchip,rk3308-i2s-tdm";
		reg = <0x00 0xff310000 0x00 0x1000>;
		interrupts = <0x00 0x31 0x04>;
		clocks = <0x02 0x50 0x02 0x52 0x02 0xa5 0x02 0x70 0x02 0x71 0x02 0x03 0x02 0x04>;
		clock-names = "mclk_tx\0mclk_rx\0hclk\0mclk_tx_src\0mclk_rx_src\0mclk_root0\0mclk_root1";
		dmas = <0x29 0x02 0x29 0x03>;
		dma-names = "tx\0rx";
		resets = <0x02 0x8c 0x02 0x8d>;
		reset-names = "tx-m\0rx-m";
		rockchip,cru = <0x02>;
		rockchip,grf = <0x4f>;
		rockchip,mclk-calibrate;
		rockchip,io-multiplex;
		status = "disabled";
		#sound-dai-cells = <0x00>;
		pinctrl-names = "default";
		pinctrl-0 = <0x60 0x61 0x62 0x19>;
		phandle = <0x95>;
	};

	i2s@ff320000 {
		compatible = "rockchip,rk3308-i2s-tdm";
		reg = <0x00 0xff320000 0x00 0x1000>;
		interrupts = <0x00 0x32 0x04>;
		clocks = <0x02 0x54 0x02 0x56 0x02 0xa6 0x02 0x72 0x02 0x73 0x02 0x03 0x02 0x04>;
		clock-names = "mclk_tx\0mclk_rx\0hclk\0mclk_tx_src\0mclk_rx_src\0mclk_root0\0mclk_root1";
		dmas = <0x29 0x04 0x29 0x05>;
		dma-names = "tx\0rx";
		resets = <0x02 0x8f 0x02 0x90>;
		reset-names = "tx-m\0rx-m";
		rockchip,cru = <0x02>;
		rockchip,grf = <0x4f>;
		rockchip,mclk-calibrate;
		status = "okay";
		rockchip,no-dmaengine;
		#sound-dai-cells = <0x00>;
		phandle = <0x8f>;
	};

	i2s@ff330000 {
		compatible = "rockchip,rk3308-i2s-tdm";
		reg = <0x00 0xff330000 0x00 0x1000>;
		interrupts = <0x00 0x33 0x04>;
		clocks = <0x02 0x58 0x02 0x5a 0x02 0xa7 0x02 0x74 0x02 0x75 0x02 0x03 0x02 0x04>;
		clock-names = "mclk_tx\0mclk_rx\0hclk\0mclk_tx_src\0mclk_rx_src\0mclk_root0\0mclk_root1";
		dmas = <0x29 0x07>;
		dma-names = "rx";
		resets = <0x02 0x92 0x02 0x93>;
		reset-names = "tx-m\0rx-m";
		rockchip,cru = <0x02>;
		rockchip,grf = <0x4f>;
		rockchip,mclk-calibrate;
		status = "disabled";
		phandle = <0xf4>;
	};

	i2s@ff350000 {
		compatible = "rockchip,rk3308-i2s\0rockchip,rk3066-i2s";
		reg = <0x00 0xff350000 0x00 0x1000>;
		interrupts = <0x00 0x34 0x04>;
		clocks = <0x02 0x5c 0x02 0xa8>;
		clock-names = "i2s_clk\0i2s_hclk";
		dmas = <0x29 0x08 0x29 0x09>;
		dma-names = "tx\0rx";
		resets = <0x02 0x95 0x02 0x94>;
		reset-names = "reset-m\0reset-h";
		pinctrl-names = "default";
		pinctrl-0 = <0x63 0x64 0x65 0x66>;
		status = "okay";
		#sound-dai-cells = <0x00>;
		rockchip,clk-trcm = <0x01>;
		phandle = <0x91>;
	};

	i2s@ff360000 {
		compatible = "rockchip,rk3308-i2s\0rockchip,rk3066-i2s";
		reg = <0x00 0xff360000 0x00 0x1000>;
		interrupts = <0x00 0x35 0x04>;
		clocks = <0x02 0x5e 0x02 0xa9>;
		clock-names = "i2s_clk\0i2s_hclk";
		dmas = <0x29 0x0b>;
		dma-names = "rx";
		resets = <0x02 0x97 0x02 0x96>;
		reset-names = "reset-m\0reset-h";
		status = "disabled";
		phandle = <0xf5>;
	};

	pdm@ff380000 {
		compatible = "rockchip,rk3308-pdm\0rockchip,pdm";
		reg = <0x00 0xff380000 0x00 0x1000>;
		clocks = <0x02 0x4b 0x02 0xa1>;
		clock-names = "pdm_clk\0pdm_hclk";
		dmas = <0x29 0x0c>;
		dma-names = "rx";
		resets = <0x02 0x83>;
		reset-names = "pdm-m";
		pinctrl-names = "default";
		pinctrl-0 = <0x67 0x68 0x69 0x6a 0x6b>;
		status = "disabled";
		phandle = <0xf6>;
	};

	spdif-tx@ff3a0000 {
		compatible = "rockchip,rk3308-spdif\0rockchip,rk3328-spdif";
		reg = <0x00 0xff3a0000 0x00 0x1000>;
		interrupts = <0x00 0x37 0x04>;
		clocks = <0x02 0x62 0x02 0xa2>;
		clock-names = "mclk\0hclk";
		dmas = <0x29 0x0d>;
		dma-names = "tx";
		pinctrl-names = "default";
		pinctrl-0 = <0x6c>;
		status = "disabled";
		phandle = <0x94>;
	};

	spdif-rx@ff3b0000 {
		compatible = "rockchip,rk3308-spdifrx";
		reg = <0x00 0xff3b0000 0x00 0x1000>;
		interrupts = <0x00 0x38 0x04>;
		clocks = <0x02 0x65 0x02 0xa3>;
		clock-names = "mclk\0hclk";
		dmas = <0x29 0x0e>;
		dma-names = "rx";
		resets = <0x02 0x87>;
		reset-names = "spdifrx-m";
		pinctrl-names = "default";
		pinctrl-0 = <0x6d>;
		status = "disabled";
		phandle = <0x93>;
	};

	vad@ff3c0000 {
		compatible = "rockchip,rk3308-vad";
		reg = <0x00 0xff3c0000 0x00 0x10000>;
		reg-names = "vad";
		clocks = <0x02 0xaa>;
		clock-names = "hclk";
		interrupts = <0x00 0x39 0x04>;
		rockchip,audio-sram = <0x6e>;
		rockchip,audio-src = <0x6f>;
		rockchip,det-channel = <0x00>;
		rockchip,mode = <0x01>;
		status = "okay";
		rockchip,buffer-time-ms = <0xc8>;
		#sound-dai-cells = <0x00>;
		phandle = <0x9e>;
	};

	usb@ff400000 {
		compatible = "rockchip,rk3066-usb\0snps,dwc2";
		reg = <0x00 0xff400000 0x00 0x40000>;
		interrupts = <0x00 0x42 0x04>;
		clocks = <0x02 0x9e>;
		clock-names = "otg";
		dr_mode = "otg";
		g-np-tx-fifo-size = <0x10>;
		g-rx-fifo-size = <0x118>;
		g-tx-fifo-size = <0x100 0x80 0x80 0x40 0x20 0x10>;
		g-use-dma;
		phys = <0x70>;
		phy-names = "usb2-phy";
		status = "okay";
		phandle = <0xf7>;
	};

	usb@ff440000 {
		compatible = "generic-ehci";
		reg = <0x00 0xff440000 0x00 0x10000>;
		interrupts = <0x00 0x47 0x04>;
		clocks = <0x02 0x9f 0x02 0xa0 0x1e>;
		clock-names = "usbhost\0arbiter\0utmi";
		phys = <0x71>;
		phy-names = "usb";
		status = "okay";
		phandle = <0xf8>;
	};

	usb@ff450000 {
		compatible = "generic-ohci";
		reg = <0x00 0xff450000 0x00 0x10000>;
		interrupts = <0x00 0x48 0x04>;
		clocks = <0x02 0x9f 0x02 0xa0 0x1e>;
		clock-names = "usbhost\0arbiter\0utmi";
		phys = <0x71>;
		phy-names = "usb";
		status = "okay";
		phandle = <0xf9>;
	};

	dwmmc@ff480000 {
		compatible = "rockchip,rk3308-dw-mshc\0rockchip,rk3288-dw-mshc";
		reg = <0x00 0xff480000 0x00 0x4000>;
		max-frequency = <0x8f0d180>;
		bus-width = <0x04>;
		clocks = <0x02 0x9a 0x02 0x30 0x02 0x31 0x02 0x32>;
		clock-names = "biu\0ciu\0ciu-drv\0ciu-sample";
		fifo-depth = <0x100>;
		interrupts = <0x00 0x4c 0x04>;
		pinctrl-names = "default";
		pinctrl-0 = <0x72 0x73 0x74 0x75>;
		status = "disabled";
		cap-mmc-highspeed;
		cap-sd-highspeed;
		supports-sd;
		card-detect-delay = <0x12c>;
		sd-uhs-sdr25;
		sd-uhs-sdr50;
		sd-uhs-sdr104;
		vmmc-supply = <0x76>;
		vqmmc-supply = <0x16>;
		phandle = <0xfa>;
	};

	dwmmc@ff490000 {
		compatible = "rockchip,rk3308-dw-mshc\0rockchip,rk3288-dw-mshc";
		reg = <0x00 0xff490000 0x00 0x4000>;
		max-frequency = <0x8f0d180>;
		bus-width = <0x08>;
		clocks = <0x02 0x9c 0x02 0x3a 0x02 0x3b 0x02 0x3c>;
		clock-names = "biu\0ciu\0ciu-drv\0ciu-sample";
		fifo-depth = <0x100>;
		interrupts = <0x00 0x4d 0x04>;
		status = "disabled";
		cap-mmc-highspeed;
		mmc-hs200-1_8v;
		supports-emmc;
		disable-wp;
		non-removable;
		num-slots = <0x01>;
		phandle = <0xfb>;
	};

	dwmmc@ff4a0000 {
		compatible = "rockchip,rk3308-dw-mshc\0rockchip,rk3288-dw-mshc";
		reg = <0x00 0xff4a0000 0x00 0x4000>;
		max-frequency = <0x8f0d180>;
		bus-width = <0x04>;
		clocks = <0x02 0x9b 0x02 0x35 0x02 0x36 0x02 0x37>;
		clock-names = "biu\0ciu\0ciu-drv\0ciu-sample";
		fifo-depth = <0x100>;
		interrupts = <0x00 0x4e 0x04>;
		pinctrl-names = "default";
		pinctrl-0 = <0x77 0x78 0x79>;
		status = "okay";
		cap-sd-highspeed;
		supports-sdio;
		ignore-pm-notify;
		keep-power-in-suspend;
		non-removable;
		mmc-pwrseq = <0x7a>;
		sd-uhs-sdr104;
		phandle = <0xfc>;
	};

	nandc@ff4b0000 {
		compatible = "rockchip,rk-nandc";
		reg = <0x00 0xff4b0000 0x00 0x4000>;
		interrupts = <0x00 0x51 0x04>;
		nandc_id = <0x00>;
		clocks = <0x02 0x2d 0x02 0x99>;
		clock-names = "clk_nandc\0hclk_nandc";
		status = "okay";
		phandle = <0xfd>;
	};

	sfc@ff4c0000 {
		compatible = "rockchip,sfc";
		reg = <0x00 0xff4c0000 0x00 0x4000>;
		interrupts = <0x00 0x52 0x04>;
		clocks = <0x02 0x3d 0x02 0x9d>;
		clock-names = "clk_sfc\0hclk_sfc";
		assigned-clocks = <0x02 0x3d>;
		assigned-clock-rates = <0x5f5e100>;
		status = "disabled";
		phandle = <0xfe>;
	};

	ethernet@ff4e0000 {
		compatible = "rockchip,rk3308-mac";
		reg = <0x00 0xff4e0000 0x00 0x10000>;
		rockchip,grf = <0x4f>;
		interrupts = <0x00 0x40 0x04>;
		interrupt-names = "macirq";
		clocks = <0x02 0x40 0x02 0x42 0x02 0x42 0x02 0x41 0x02 0x40 0x02 0x86 0x02 0xc3 0x02 0x43>;
		clock-names = "stmmaceth\0mac_clk_rx\0mac_clk_tx\0clk_mac_ref\0clk_mac_refout\0aclk_mac\0pclk_mac\0clk_mac_speed";
		phy-mode = "rmii";
		pinctrl-names = "default";
		pinctrl-0 = <0x7b 0x7c>;
		resets = <0x02 0x7d>;
		reset-names = "stmmaceth";
		status = "disable";
		phy-supply = <0x7d>;
		assigned-clocks = <0x02 0x40>;
		assigned-clock-parents = <0x7e>;
		clock_in_out = "input";
		snps,reset-gpio = <0x1a 0x0a 0x01>;
		snps,reset-active-low;
		snps,reset-delays-us = <0x00 0xc350 0xc350>;
		phandle = <0xff>;
	};

	clock-controller@ff500000 {
		compatible = "rockchip,rk3308-cru";
		reg = <0x00 0xff500000 0x00 0x1000>;
		rockchip,grf = <0x4f>;
		rockchip,boost = <0x7f>;
		#clock-cells = <0x01>;
		#reset-cells = <0x01>;
		assigned-clocks = <0x02 0x0f>;
		assigned-clock-rates = <0x8000>;
		phandle = <0x02>;
	};

	cpu-boost@ff550000 {
		compatible = "syscon";
		reg = <0x00 0xff550000 0x00 0x1000>;
		phandle = <0x7f>;
	};

	acodec@ff560000 {
		compatible = "rockchip,rk3308-codec";
		reg = <0x00 0xff560000 0x00 0x10000>;
		rockchip,grf = <0x4f>;
		rockchip,detect-grf = <0x80>;
		interrupts = <0x00 0x72 0x04 0x00 0x73 0x04>;
		clocks = <0x02 0xc4 0x02 0x55 0x02 0x57>;
		clock-names = "acodec\0mclk_tx\0mclk_rx";
		resets = <0x02 0x99>;
		reset-names = "acodec-reset";
		status = "okay";
		rockchip,no-deep-low-power;
		rockchip,loopback-grp = <0x00>;
		hp-ctl-gpios = <0x1a 0x01 0x00>;
		spk-ctl-gpios = <0x1a 0x05 0x00>;
		phandle = <0x90>;
	};

	interrupt-controller@ff580000 {
		compatible = "arm,gic-400";
		#interrupt-cells = <0x03>;
		#address-cells = <0x00>;
		interrupt-controller;
		reg = <0x00 0xff581000 0x00 0x1000 0x00 0xff582000 0x00 0x2000 0x00 0xff584000 0x00 0x2000 0x00 0xff586000 0x00 0x2000>;
		interrupts = <0x01 0x09 0x04>;
		phandle = <0x01>;
	};

	sram@fff80000 {
		compatible = "mmio-sram";
		reg = <0x00 0xfff80000 0x00 0x40000>;
		#address-cells = <0x01>;
		#size-cells = <0x01>;
		ranges = <0x00 0x00 0xfff80000 0x40000>;
		phandle = <0x100>;

		ddr-sram@0 {
			reg = <0x00 0x8000>;
		};

		vad-sram@8000 {
			reg = <0x8000 0x38000>;
			phandle = <0x6e>;
		};
	};

	rockchip-system-monitor {
		compatible = "rockchip,system-monitor";
		rockchip,thermal-zone = "soc-thermal";
		rockchip,polling-delay = <0xc8>;
		phandle = <0x101>;
	};

	pinctrl {
		compatible = "rockchip,rk3308-pinctrl";
		rockchip,grf = <0x4f>;
		#address-cells = <0x02>;
		#size-cells = <0x02>;
		ranges;
		pinctrl-names = "default";
		pinctrl-0 = <0x81>;
		phandle = <0x102>;

		gpio0@ff220000 {
			compatible = "rockchip,gpio-bank";
			reg = <0x00 0xff220000 0x00 0x100>;
			interrupts = <0x00 0x28 0x04>;
			clocks = <0x02 0xd7>;
			gpio-controller;
			#gpio-cells = <0x02>;
			interrupt-controller;
			#interrupt-cells = <0x02>;
			phandle = <0x1a>;
		};

		gpio1@ff230000 {
			compatible = "rockchip,gpio-bank";
			reg = <0x00 0xff230000 0x00 0x100>;
			interrupts = <0x00 0x29 0x04>;
			clocks = <0x02 0xd8>;
			gpio-controller;
			#gpio-cells = <0x02>;
			interrupt-controller;
			#interrupt-cells = <0x02>;
			phandle = <0x1b>;
		};

		gpio2@ff240000 {
			compatible = "rockchip,gpio-bank";
			reg = <0x00 0xff240000 0x00 0x100>;
			interrupts = <0x00 0x2a 0x04>;
			clocks = <0x02 0xd9>;
			gpio-controller;
			#gpio-cells = <0x02>;
			interrupt-controller;
			#interrupt-cells = <0x02>;
			phandle = <0x103>;
		};

		gpio3@ff250000 {
			compatible = "rockchip,gpio-bank";
			reg = <0x00 0xff250000 0x00 0x100>;
			interrupts = <0x00 0x2b 0x04>;
			clocks = <0x02 0xda>;
			gpio-controller;
			#gpio-cells = <0x02>;
			interrupt-controller;
			#interrupt-cells = <0x02>;
			phandle = <0x104>;
		};

		gpio4@ff260000 {
			compatible = "rockchip,gpio-bank";
			reg = <0x00 0xff260000 0x00 0x100>;
			interrupts = <0x00 0x2c 0x04>;
			clocks = <0x02 0xdb>;
			gpio-controller;
			#gpio-cells = <0x02>;
			interrupt-controller;
			#interrupt-cells = <0x02>;
			phandle = <0x98>;
		};

		pcfg-pull-up {
			bias-pull-up;
			phandle = <0x86>;
		};

		pcfg-pull-down {
			bias-pull-down;
			phandle = <0x82>;
		};

		pcfg-pull-none {
			bias-disable;
			phandle = <0x84>;
		};

		pcfg-pull-none-2ma {
			bias-disable;
			drive-strength = <0x02>;
			phandle = <0x105>;
		};

		pcfg-pull-up-2ma {
			bias-pull-up;
			drive-strength = <0x02>;
			phandle = <0x106>;
		};

		pcfg-pull-up-4ma {
			bias-pull-up;
			drive-strength = <0x04>;
			phandle = <0x87>;
		};

		pcfg-pull-none-4ma {
			bias-disable;
			drive-strength = <0x04>;
			phandle = <0x85>;
		};

		pcfg-pull-down-4ma {
			bias-pull-down;
			drive-strength = <0x04>;
			phandle = <0x107>;
		};

		pcfg-pull-none-8ma {
			bias-disable;
			drive-strength = <0x08>;
			phandle = <0x89>;
		};

		pcfg-pull-up-8ma {
			bias-pull-up;
			drive-strength = <0x08>;
			phandle = <0x88>;
		};

		pcfg-pull-none-12ma {
			bias-disable;
			drive-strength = <0x0c>;
			phandle = <0x8b>;
		};

		pcfg-pull-up-12ma {
			bias-pull-up;
			drive-strength = <0x0c>;
			phandle = <0x8a>;
		};

		pcfg-pull-none-smt {
			bias-disable;
			input-schmitt-enable;
			phandle = <0x83>;
		};

		pcfg-output-high {
			output-high;
			phandle = <0x108>;
		};

		pcfg-output-low {
			output-low;
			phandle = <0x109>;
		};

		pcfg-input-high {
			bias-pull-up;
			input-enable;
			phandle = <0x10a>;
		};

		pcfg-input {
			input-enable;
			phandle = <0x10b>;
		};

		ext_micbias {

			ext-micbias-en {
				rockchip,pins = <0x00 0x12 0x00 0x82>;
				phandle = <0x10c>;
			};
		};

		i2c0 {

			i2c0-xfer {
				rockchip,pins = <0x01 0x18 0x02 0x83 0x01 0x19 0x02 0x83>;
				phandle = <0x17>;
			};
		};

		i2c1 {

			i2c1-xfer {
				rockchip,pins = <0x00 0x0b 0x01 0x83 0x00 0x0c 0x01 0x83>;
				phandle = <0x18>;
			};
		};

		i2c2 {

			i2c2-xfer {
				rockchip,pins = <0x02 0x02 0x03 0x83 0x02 0x03 0x03 0x83>;
				phandle = <0x1c>;
			};
		};

		i2c3-m0 {

			i2c3m0-xfer {
				rockchip,pins = <0x00 0x0f 0x02 0x83 0x00 0x10 0x02 0x83>;
				phandle = <0x1d>;
			};
		};

		i2c3-m1 {

			i2c3m1-xfer {
				rockchip,pins = <0x03 0x0c 0x02 0x83 0x03 0x0d 0x02 0x83>;
				phandle = <0x10d>;
			};
		};

		i2c3-m2 {

			i2c3m2-xfer {
				rockchip,pins = <0x02 0x01 0x03 0x83 0x02 0x00 0x03 0x83>;
				phandle = <0x10e>;
			};
		};

		i2s_2ch_0 {

			i2s-2ch-0-mclk {
				rockchip,pins = <0x04 0x0c 0x01 0x84>;
				phandle = <0x10f>;
			};

			i2s-2ch-0-sclk {
				rockchip,pins = <0x04 0x0d 0x01 0x84>;
				phandle = <0x63>;
			};

			i2s-2ch-0-lrck {
				rockchip,pins = <0x04 0x0e 0x01 0x84>;
				phandle = <0x64>;
			};

			i2s-2ch-0-sdo {
				rockchip,pins = <0x04 0x0f 0x01 0x84>;
				phandle = <0x66>;
			};

			i2s-2ch-0-sdi {
				rockchip,pins = <0x04 0x10 0x01 0x84>;
				phandle = <0x65>;
			};
		};

		i2s_8ch_0 {

			i2s-8ch-0-mclk {
				rockchip,pins = <0x02 0x04 0x01 0x84>;
				phandle = <0x5f>;
			};

			i2s-8ch-0-sclktx {
				rockchip,pins = <0x02 0x05 0x01 0x84>;
				phandle = <0x53>;
			};

			i2s-8ch-0-sclkrx {
				rockchip,pins = <0x02 0x06 0x01 0x84>;
				phandle = <0x54>;
			};

			i2s-8ch-0-lrcktx {
				rockchip,pins = <0x02 0x07 0x01 0x84>;
				phandle = <0x55>;
			};

			i2s-8ch-0-lrckrx {
				rockchip,pins = <0x02 0x08 0x01 0x84>;
				phandle = <0x56>;
			};

			i2s-8ch-0-sdo0 {
				rockchip,pins = <0x02 0x09 0x01 0x84>;
				phandle = <0x5b>;
			};

			i2s-8ch-0-sdo1 {
				rockchip,pins = <0x02 0x0a 0x01 0x84>;
				phandle = <0x5c>;
			};

			i2s-8ch-0-sdo2 {
				rockchip,pins = <0x02 0x0b 0x01 0x84>;
				phandle = <0x5d>;
			};

			i2s-8ch-0-sdo3 {
				rockchip,pins = <0x02 0x0c 0x01 0x84>;
				phandle = <0x5e>;
			};

			i2s-8ch-0-sdi0 {
				rockchip,pins = <0x02 0x0d 0x01 0x84>;
				phandle = <0x57>;
			};

			i2s-8ch-0-sdi1 {
				rockchip,pins = <0x02 0x0e 0x01 0x84>;
				phandle = <0x58>;
			};

			i2s-8ch-0-sdi2 {
				rockchip,pins = <0x02 0x0f 0x01 0x84>;
				phandle = <0x59>;
			};

			i2s-8ch-0-sdi3 {
				rockchip,pins = <0x02 0x10 0x01 0x84>;
				phandle = <0x5a>;
			};
		};

		i2s_8ch_1_m0 {

			i2s-8ch-1-m0-mclk {
				rockchip,pins = <0x01 0x02 0x02 0x84>;
				phandle = <0x19>;
			};

			i2s-8ch-1-m0-sclktx {
				rockchip,pins = <0x01 0x03 0x02 0x84>;
				phandle = <0x60>;
			};

			i2s-8ch-1-m0-sclkrx {
				rockchip,pins = <0x01 0x04 0x02 0x84>;
				phandle = <0x110>;
			};

			i2s-8ch-1-m0-lrcktx {
				rockchip,pins = <0x01 0x05 0x02 0x84>;
				phandle = <0x61>;
			};

			i2s-8ch-1-m0-lrckrx {
				rockchip,pins = <0x01 0x06 0x02 0x84>;
				phandle = <0x111>;
			};

			i2s-8ch-1-m0-sdo0 {
				rockchip,pins = <0x01 0x07 0x02 0x84>;
				phandle = <0x62>;
			};

			i2s-8ch-1-m0-sdo1-sdi3 {
				rockchip,pins = <0x01 0x08 0x02 0x84>;
				phandle = <0x112>;
			};

			i2s-8ch-1-m0-sdo2-sdi2 {
				rockchip,pins = <0x01 0x09 0x02 0x84>;
				phandle = <0x113>;
			};

			i2s-8ch-1-m0-sdo3_sdi1 {
				rockchip,pins = <0x01 0x0a 0x02 0x84>;
				phandle = <0x114>;
			};

			i2s-8ch-1-m0-sdi0 {
				rockchip,pins = <0x01 0x0b 0x02 0x84>;
				phandle = <0x115>;
			};
		};

		i2s_8ch_1_m1 {

			i2s-8ch-1-m1-mclk {
				rockchip,pins = <0x01 0x0c 0x02 0x84>;
				phandle = <0x116>;
			};

			i2s-8ch-1-m1-sclktx {
				rockchip,pins = <0x01 0x0d 0x02 0x84>;
				phandle = <0x117>;
			};

			i2s-8ch-1-m1-sclkrx {
				rockchip,pins = <0x01 0x0e 0x02 0x84>;
				phandle = <0x118>;
			};

			i2s-8ch-1-m1-lrcktx {
				rockchip,pins = <0x01 0x0f 0x02 0x84>;
				phandle = <0x119>;
			};

			i2s-8ch-1-m1-lrckrx {
				rockchip,pins = <0x01 0x10 0x02 0x84>;
				phandle = <0x11a>;
			};

			i2s-8ch-1-m1-sdo0 {
				rockchip,pins = <0x01 0x11 0x02 0x84>;
				phandle = <0x11b>;
			};

			i2s-8ch-1-m1-sdo1-sdi3 {
				rockchip,pins = <0x01 0x12 0x02 0x84>;
				phandle = <0x11c>;
			};

			i2s-8ch-1-m1-sdo2-sdi2 {
				rockchip,pins = <0x01 0x13 0x02 0x84>;
				phandle = <0x11d>;
			};

			i2s-8ch-1-m1-sdo3_sdi1 {
				rockchip,pins = <0x01 0x14 0x02 0x84>;
				phandle = <0x11e>;
			};

			i2s-8ch-1-m1-sdi0 {
				rockchip,pins = <0x01 0x15 0x02 0x84>;
				phandle = <0x11f>;
			};
		};

		lcdc {

			lcdc-ctl {
				rockchip,pins = <0x01 0x00 0x01 0x85 0x01 0x01 0x01 0x85 0x01 0x02 0x01 0x85 0x01 0x03 0x01 0x85 0x01 0x04 0x01 0x85 0x01 0x05 0x01 0x85 0x01 0x06 0x01 0x85 0x01 0x07 0x01 0x85 0x01 0x08 0x01 0x85 0x01 0x09 0x01 0x85 0x01 0x0a 0x01 0x85 0x01 0x0b 0x01 0x85 0x01 0x0c 0x01 0x85 0x01 0x0d 0x01 0x85 0x01 0x0e 0x01 0x85 0x01 0x0f 0x01 0x85 0x01 0x10 0x01 0x85 0x01 0x11 0x01 0x85 0x01 0x12 0x01 0x85 0x01 0x13 0x01 0x85 0x01 0x14 0x01 0x85 0x01 0x15 0x01 0x85>;
				phandle = <0x13>;
			};

			lcdc-rgb888-m0 {
				rockchip,pins = <0x01 0x16 0x06 0x85 0x01 0x17 0x06 0x85 0x02 0x09 0x03 0x85 0x02 0x0a 0x03 0x85 0x02 0x0f 0x03 0x85 0x02 0x10 0x03 0x85>;
				phandle = <0x120>;
			};

			lcdc-rgb888-m1 {
				rockchip,pins = <0x03 0x06 0x03 0x85 0x03 0x07 0x03 0x85 0x03 0x08 0x03 0x85 0x03 0x09 0x03 0x85 0x03 0x0a 0x04 0x85 0x03 0x0b 0x04 0x85>;
				phandle = <0x121>;
			};
		};

		pdm_m0 {

			pdm-m0-clk {
				rockchip,pins = <0x01 0x04 0x03 0x84>;
				phandle = <0x122>;
			};

			pdm-m0-sdi0 {
				rockchip,pins = <0x01 0x0b 0x03 0x84>;
				phandle = <0x123>;
			};

			pdm-m0-sdi1 {
				rockchip,pins = <0x01 0x0a 0x03 0x84>;
				phandle = <0x124>;
			};

			pdm-m0-sdi2 {
				rockchip,pins = <0x01 0x09 0x03 0x84>;
				phandle = <0x125>;
			};

			pdm-m0-sdi3 {
				rockchip,pins = <0x01 0x08 0x03 0x84>;
				phandle = <0x126>;
			};
		};

		pdm_m1 {

			pdm-m1-clk {
				rockchip,pins = <0x01 0x0e 0x04 0x84>;
				phandle = <0x127>;
			};

			pdm-m1-sdi0 {
				rockchip,pins = <0x01 0x15 0x04 0x84>;
				phandle = <0x128>;
			};

			pdm-m1-sdi1 {
				rockchip,pins = <0x01 0x14 0x04 0x84>;
				phandle = <0x129>;
			};

			pdm-m1-sdi2 {
				rockchip,pins = <0x01 0x13 0x04 0x84>;
				phandle = <0x12a>;
			};

			pdm-m1-sdi3 {
				rockchip,pins = <0x01 0x12 0x04 0x84>;
				phandle = <0x12b>;
			};
		};

		pdm_m2 {

			pdm-m2-clkm {
				rockchip,pins = <0x02 0x04 0x03 0x84>;
				phandle = <0x12c>;
			};

			pdm-m2-clk {
				rockchip,pins = <0x02 0x06 0x02 0x84>;
				phandle = <0x67>;
			};

			pdm-m2-sdi0 {
				rockchip,pins = <0x02 0x0d 0x02 0x84>;
				phandle = <0x68>;
			};

			pdm-m2-sdi1 {
				rockchip,pins = <0x02 0x0e 0x02 0x84>;
				phandle = <0x69>;
			};

			pdm-m2-sdi2 {
				rockchip,pins = <0x02 0x0f 0x02 0x84>;
				phandle = <0x6a>;
			};

			pdm-m2-sdi3 {
				rockchip,pins = <0x02 0x10 0x02 0x84>;
				phandle = <0x6b>;
			};
		};

		spdif_in {

			spdif-in {
				rockchip,pins = <0x00 0x12 0x01 0x84>;
				phandle = <0x6d>;
			};
		};

		spdif_out {

			spdif-out {
				rockchip,pins = <0x00 0x11 0x01 0x84>;
				phandle = <0x6c>;
			};
		};

		tsadc {

			tsadc-otp-gpio {
				rockchip,pins = <0x00 0x0a 0x00 0x84>;
				phandle = <0x50>;
			};

			tsadc-otp-out {
				rockchip,pins = <0x00 0x0a 0x01 0x84>;
				phandle = <0x51>;
			};
		};

		uart0 {

			uart0-xfer {
				rockchip,pins = <0x02 0x01 0x01 0x86 0x02 0x00 0x01 0x86>;
				phandle = <0x21>;
			};

			uart0-cts {
				rockchip,pins = <0x02 0x02 0x01 0x84>;
				phandle = <0x22>;
			};

			uart0-rts {
				rockchip,pins = <0x02 0x03 0x01 0x84>;
				phandle = <0x23>;
			};

			uart0-rts-gpio {
				rockchip,pins = <0x02 0x03 0x00 0x84>;
				phandle = <0x12d>;
			};
		};

		uart1 {

			uart1-xfer {
				rockchip,pins = <0x01 0x19 0x01 0x86 0x01 0x18 0x01 0x86>;
				phandle = <0x24>;
			};

			uart1-cts {
				rockchip,pins = <0x01 0x16 0x01 0x84>;
				phandle = <0x25>;
			};

			uart1-rts {
				rockchip,pins = <0x01 0x17 0x01 0x84>;
				phandle = <0x26>;
			};
		};

		uart2-m0 {

			uart2m0-xfer {
				rockchip,pins = <0x01 0x17 0x02 0x86 0x01 0x16 0x02 0x86>;
				phandle = <0x27>;
			};
		};

		uart2-m1 {

			uart2m1-xfer {
				rockchip,pins = <0x04 0x1b 0x02 0x86 0x04 0x1a 0x02 0x86>;
				phandle = <0x12e>;
			};
		};

		uart3 {

			uart3-xfer {
				rockchip,pins = <0x03 0x0d 0x04 0x86 0x03 0x0c 0x04 0x86>;
				phandle = <0x28>;
			};
		};

		uart3-m1 {

			uart3m1-xfer {
				rockchip,pins = <0x00 0x12 0x03 0x86 0x00 0x11 0x03 0x86>;
				phandle = <0x12f>;
			};
		};

		uart4 {

			uart4-xfer {
				rockchip,pins = <0x04 0x09 0x01 0x86 0x04 0x08 0x01 0x86>;
				phandle = <0x2a>;
			};

			uart4-cts {
				rockchip,pins = <0x04 0x06 0x01 0x84>;
				phandle = <0x2b>;
			};

			uart4-rts {
				rockchip,pins = <0x04 0x07 0x01 0x84>;
				phandle = <0x9a>;
			};

			uart4-rts-gpio {
				rockchip,pins = <0x04 0x07 0x00 0x84>;
				phandle = <0x9b>;
			};
		};

		spi0 {

			spi0-clk {
				rockchip,pins = <0x02 0x02 0x02 0x87>;
				phandle = <0x2c>;
			};

			spi0-csn0 {
				rockchip,pins = <0x02 0x03 0x02 0x87>;
				phandle = <0x2d>;
			};

			spi0-miso {
				rockchip,pins = <0x02 0x00 0x02 0x87>;
				phandle = <0x2e>;
			};

			spi0-mosi {
				rockchip,pins = <0x02 0x01 0x02 0x87>;
				phandle = <0x2f>;
			};

			spi0-clk-hs {
				rockchip,pins = <0x02 0x02 0x02 0x88>;
				phandle = <0x30>;
			};

			spi0-miso-hs {
				rockchip,pins = <0x02 0x00 0x02 0x88>;
				phandle = <0x31>;
			};

			spi0-mosi-hs {
				rockchip,pins = <0x02 0x01 0x02 0x88>;
				phandle = <0x32>;
			};
		};

		spi1 {

			spi1-clk {
				rockchip,pins = <0x03 0x0b 0x03 0x87>;
				phandle = <0x33>;
			};

			spi1-csn0 {
				rockchip,pins = <0x03 0x0d 0x03 0x87>;
				phandle = <0x34>;
			};

			spi1-miso {
				rockchip,pins = <0x03 0x0a 0x03 0x87>;
				phandle = <0x35>;
			};

			spi1-mosi {
				rockchip,pins = <0x03 0x0c 0x03 0x87>;
				phandle = <0x36>;
			};

			spi1-clk-hs {
				rockchip,pins = <0x03 0x0b 0x03 0x88>;
				phandle = <0x37>;
			};

			spi1-miso-hs {
				rockchip,pins = <0x03 0x0a 0x03 0x88>;
				phandle = <0x38>;
			};

			spi1-mosi-hs {
				rockchip,pins = <0x03 0x0c 0x03 0x88>;
				phandle = <0x39>;
			};
		};

		spi1-m1 {

			spi1m1-miso {
				rockchip,pins = <0x02 0x04 0x02 0x87>;
				phandle = <0x130>;
			};

			spi1m1-mosi {
				rockchip,pins = <0x02 0x05 0x02 0x87>;
				phandle = <0x131>;
			};

			spi1m1-clk {
				rockchip,pins = <0x02 0x07 0x02 0x87>;
				phandle = <0x132>;
			};

			spi1m1-csn0 {
				rockchip,pins = <0x02 0x09 0x02 0x87>;
				phandle = <0x133>;
			};

			spi1m1-miso-hs {
				rockchip,pins = <0x02 0x04 0x02 0x88>;
				phandle = <0x134>;
			};

			spi1m1-mosi-hs {
				rockchip,pins = <0x02 0x05 0x02 0x88>;
				phandle = <0x135>;
			};

			spi1m1-clk-hs {
				rockchip,pins = <0x02 0x07 0x02 0x88>;
				phandle = <0x136>;
			};

			spi1m1-csn0-hs {
				rockchip,pins = <0x02 0x09 0x02 0x88>;
				phandle = <0x137>;
			};
		};

		spi2 {

			spi2-clk {
				rockchip,pins = <0x01 0x18 0x03 0x87>;
				phandle = <0x3a>;
			};

			spi2-csn0 {
				rockchip,pins = <0x01 0x19 0x03 0x87>;
				phandle = <0x3b>;
			};

			spi2-miso {
				rockchip,pins = <0x01 0x16 0x03 0x87>;
				phandle = <0x3c>;
			};

			spi2-mosi {
				rockchip,pins = <0x01 0x17 0x03 0x87>;
				phandle = <0x3d>;
			};

			spi2-clk-hs {
				rockchip,pins = <0x01 0x18 0x03 0x88>;
				phandle = <0x3e>;
			};

			spi2-miso-hs {
				rockchip,pins = <0x01 0x16 0x03 0x88>;
				phandle = <0x3f>;
			};

			spi2-mosi-hs {
				rockchip,pins = <0x01 0x17 0x03 0x88>;
				phandle = <0x40>;
			};
		};

		sdmmc {

			sdmmc-clk {
				rockchip,pins = <0x04 0x1d 0x01 0x85>;
				phandle = <0x72>;
			};

			sdmmc-cmd {
				rockchip,pins = <0x04 0x1c 0x01 0x87>;
				phandle = <0x73>;
			};

			sdmmc-det {
				rockchip,pins = <0x00 0x03 0x01 0x87>;
				phandle = <0x74>;
			};

			sdmmc-pwren {
				rockchip,pins = <0x04 0x1e 0x01 0x85>;
				phandle = <0x138>;
			};

			sdmmc-bus1 {
				rockchip,pins = <0x04 0x18 0x01 0x87>;
				phandle = <0x139>;
			};

			sdmmc-bus4 {
				rockchip,pins = <0x04 0x18 0x01 0x87 0x04 0x19 0x01 0x87 0x04 0x1a 0x01 0x87 0x04 0x1b 0x01 0x87>;
				phandle = <0x75>;
			};

			sdmmc-gpio {
				rockchip,pins = <0x04 0x18 0x00 0x87 0x04 0x19 0x00 0x87 0x04 0x1a 0x00 0x87 0x04 0x1b 0x00 0x87 0x04 0x1c 0x00 0x87 0x04 0x1d 0x00 0x87 0x04 0x1e 0x00 0x87>;
				phandle = <0x13a>;
			};
		};

		sdio {

			sdio-clk {
				rockchip,pins = <0x04 0x05 0x01 0x89>;
				phandle = <0x79>;
			};

			sdio-cmd {
				rockchip,pins = <0x04 0x04 0x01 0x88>;
				phandle = <0x78>;
			};

			sdio-pwren {
				rockchip,pins = <0x00 0x02 0x01 0x89>;
				phandle = <0x13b>;
			};

			sdio-wrpt {
				rockchip,pins = <0x00 0x01 0x01 0x89>;
				phandle = <0x13c>;
			};

			sdio-intn {
				rockchip,pins = <0x00 0x00 0x01 0x89>;
				phandle = <0x13d>;
			};

			sdio-bus1 {
				rockchip,pins = <0x04 0x00 0x01 0x88>;
				phandle = <0x13e>;
			};

			sdio-bus4 {
				rockchip,pins = <0x04 0x00 0x01 0x88 0x04 0x01 0x01 0x88 0x04 0x02 0x01 0x88 0x04 0x03 0x01 0x88>;
				phandle = <0x77>;
			};

			sdio-gpio {
				rockchip,pins = <0x04 0x00 0x00 0x87 0x04 0x01 0x00 0x87 0x04 0x02 0x00 0x87 0x04 0x03 0x00 0x87 0x04 0x04 0x00 0x87 0x04 0x05 0x00 0x87>;
				phandle = <0x13f>;
			};
		};

		emmc {

			emmc-clk {
				rockchip,pins = <0x03 0x09 0x02 0x89>;
				phandle = <0x140>;
			};

			emmc-cmd {
				rockchip,pins = <0x03 0x08 0x02 0x88>;
				phandle = <0x141>;
			};

			emmc-pwren {
				rockchip,pins = <0x03 0x0b 0x02 0x84>;
				phandle = <0x142>;
			};

			emmc-rstn {
				rockchip,pins = <0x03 0x0a 0x02 0x84>;
				phandle = <0x143>;
			};

			emmc-bus1 {
				rockchip,pins = <0x03 0x00 0x02 0x88>;
				phandle = <0x144>;
			};

			emmc-bus4 {
				rockchip,pins = <0x03 0x00 0x02 0x88 0x03 0x01 0x02 0x88 0x03 0x02 0x02 0x88 0x03 0x03 0x02 0x88>;
				phandle = <0x145>;
			};

			emmc-bus8 {
				rockchip,pins = <0x03 0x00 0x02 0x88 0x03 0x01 0x02 0x88 0x03 0x02 0x02 0x88 0x03 0x03 0x02 0x88 0x03 0x04 0x02 0x88 0x03 0x05 0x02 0x88 0x03 0x06 0x02 0x88 0x03 0x07 0x02 0x88>;
				phandle = <0x146>;
			};
		};

		flash {

			flash-csn0 {
				rockchip,pins = <0x03 0x0d 0x01 0x84>;
				phandle = <0x147>;
			};

			flash-rdy {
				rockchip,pins = <0x03 0x0c 0x01 0x84>;
				phandle = <0x148>;
			};

			flash-ale {
				rockchip,pins = <0x03 0x0b 0x01 0x84>;
				phandle = <0x149>;
			};

			flash-cle {
				rockchip,pins = <0x03 0x09 0x01 0x84>;
				phandle = <0x14a>;
			};

			flash-wrn {
				rockchip,pins = <0x03 0x08 0x01 0x84>;
				phandle = <0x14b>;
			};

			flash-rdn {
				rockchip,pins = <0x03 0x0a 0x01 0x84>;
				phandle = <0x14c>;
			};

			flash-bus8 {
				rockchip,pins = <0x03 0x00 0x01 0x8a 0x03 0x01 0x01 0x8a 0x03 0x02 0x01 0x8a 0x03 0x03 0x01 0x8a 0x03 0x04 0x01 0x8a 0x03 0x05 0x01 0x8a 0x03 0x06 0x01 0x8a 0x03 0x07 0x01 0x8a>;
				phandle = <0x14d>;
			};
		};

		pwm0 {

			pwm0-pin {
				rockchip,pins = <0x00 0x0d 0x01 0x84>;
				phandle = <0x14e>;
			};

			pwm0-pin-pull-down {
				rockchip,pins = <0x00 0x0d 0x01 0x82>;
				phandle = <0x49>;
			};
		};

		pwm1 {

			pwm1-pin {
				rockchip,pins = <0x00 0x0e 0x01 0x84>;
				phandle = <0x4a>;
			};

			pwm1-pin-pull-down {
				rockchip,pins = <0x00 0x0e 0x01 0x82>;
				phandle = <0x14f>;
			};
		};

		pwm2 {

			pwm2-pin {
				rockchip,pins = <0x00 0x0f 0x01 0x84>;
				phandle = <0x4b>;
			};

			pwm2-pin-pull-down {
				rockchip,pins = <0x00 0x0f 0x01 0x82>;
				phandle = <0x150>;
			};
		};

		pwm3 {

			pwm3-pin {
				rockchip,pins = <0x00 0x10 0x01 0x84>;
				phandle = <0x4c>;
			};

			pwm3-pin-pull-down {
				rockchip,pins = <0x00 0x10 0x01 0x82>;
				phandle = <0x151>;
			};
		};

		pwm4 {

			pwm4-pin {
				rockchip,pins = <0x00 0x01 0x02 0x84>;
				phandle = <0x45>;
			};

			pwm4-pin-pull-down {
				rockchip,pins = <0x00 0x01 0x02 0x82>;
				phandle = <0x152>;
			};
		};

		pwm5 {

			pwm5-pin {
				rockchip,pins = <0x00 0x11 0x02 0x84>;
				phandle = <0x46>;
			};

			pwm5-pin-pull-down {
				rockchip,pins = <0x00 0x11 0x02 0x82>;
				phandle = <0x153>;
			};
		};

		pwm6 {

			pwm6-pin {
				rockchip,pins = <0x00 0x12 0x02 0x84>;
				phandle = <0x47>;
			};

			pwm6-pin-pull-down {
				rockchip,pins = <0x00 0x12 0x02 0x82>;
				phandle = <0x154>;
			};
		};

		pwm7 {

			pwm7-pin {
				rockchip,pins = <0x02 0x08 0x02 0x84>;
				phandle = <0x48>;
			};

			pwm7-pin-pull-down {
				rockchip,pins = <0x02 0x08 0x02 0x82>;
				phandle = <0x155>;
			};
		};

		pwm8 {

			pwm8-pin {
				rockchip,pins = <0x02 0x0a 0x02 0x84>;
				phandle = <0x41>;
			};

			pwm8-pin-pull-down {
				rockchip,pins = <0x02 0x0a 0x02 0x82>;
				phandle = <0x156>;
			};
		};

		pwm9 {

			pwm9-pin {
				rockchip,pins = <0x02 0x0b 0x02 0x84>;
				phandle = <0x42>;
			};

			pwm9-pin-pull-down {
				rockchip,pins = <0x02 0x0b 0x02 0x82>;
				phandle = <0x157>;
			};
		};

		pwm10 {

			pwm10-pin {
				rockchip,pins = <0x02 0x0c 0x02 0x84>;
				phandle = <0x43>;
			};

			pwm10-pin-pull-down {
				rockchip,pins = <0x02 0x0c 0x02 0x82>;
				phandle = <0x158>;
			};
		};

		pwm11 {

			pwm11-pin {
				rockchip,pins = <0x02 0x10 0x04 0x84>;
				phandle = <0x44>;
			};

			pwm11-pin-pull-down {
				rockchip,pins = <0x02 0x10 0x04 0x82>;
				phandle = <0x159>;
			};
		};

		gmac {

			rmii-pins {
				rockchip,pins = <0x01 0x11 0x03 0x8b 0x01 0x13 0x03 0x8b 0x01 0x12 0x03 0x8b 0x01 0x14 0x03 0x84 0x01 0x15 0x03 0x84 0x01 0x0f 0x03 0x84 0x01 0x10 0x03 0x84 0x01 0x0e 0x03 0x84 0x01 0x0d 0x03 0x84>;
				phandle = <0x7b>;
			};

			mac-refclk-12ma {
				rockchip,pins = <0x01 0x0c 0x03 0x8b>;
				phandle = <0x15a>;
			};

			mac-refclk {
				rockchip,pins = <0x01 0x0c 0x03 0x84>;
				phandle = <0x7c>;
			};
		};

		gmac-m1 {

			rmiim1-pins {
				rockchip,pins = <0x04 0x0f 0x02 0x8b 0x04 0x05 0x02 0x8b 0x04 0x04 0x02 0x8b 0x04 0x02 0x02 0x84 0x04 0x03 0x02 0x84 0x04 0x00 0x02 0x84 0x04 0x01 0x02 0x84 0x04 0x0e 0x02 0x84 0x04 0x0d 0x02 0x84>;
				phandle = <0x15b>;
			};

			macm1-refclk-12ma {
				rockchip,pins = <0x04 0x0c 0x02 0x8b>;
				phandle = <0x15c>;
			};

			macm1-refclk {
				rockchip,pins = <0x04 0x0c 0x02 0x84>;
				phandle = <0x15d>;
			};
		};

		rtc {

			rtc-32k {
				rockchip,pins = <0x00 0x13 0x01 0x84>;
				phandle = <0x81>;
			};
		};

		can-m0 {

			canm0-pins {
				rockchip,pins = <0x00 0x0b 0x02 0x84 0x00 0x0c 0x02 0x84>;
				phandle = <0x15e>;
			};
		};

		can-m1 {

			canm1-pins {
				rockchip,pins = <0x01 0x16 0x05 0x84 0x01 0x17 0x05 0x84>;
				phandle = <0x15f>;
			};
		};

		can-m2 {

			canm2-pins {
				rockchip,pins = <0x02 0x02 0x04 0x84 0x02 0x03 0x04 0x84>;
				phandle = <0x160>;
			};
		};

		owire-m0 {

			owirem0-pins {
				rockchip,pins = <0x00 0x0b 0x03 0x84>;
				phandle = <0x161>;
			};
		};

		owire-m1 {

			owirem1-pins {
				rockchip,pins = <0x01 0x16 0x07 0x84>;
				phandle = <0x162>;
			};
		};

		owire-m2 {

			owirem2-pins {
				rockchip,pins = <0x02 0x02 0x05 0x84>;
				phandle = <0x163>;
			};
		};

		buttons {

			pwr-key {
				rockchip,pins = <0x00 0x06 0x00 0x86>;
				phandle = <0x8d>;
			};
		};

		usb {

			usb-drv {
				rockchip,pins = <0x00 0x15 0x00 0x84>;
				phandle = <0x99>;
			};
		};

		sdio-pwrseq {

			wifi-enable-h {
				rockchip,pins = <0x00 0x02 0x00 0x84>;
				phandle = <0x8e>;
			};
		};

		wireless-wlan {

			wifi-wake-host {
				rockchip,pins = <0x00 0x00 0x00 0x86>;
				phandle = <0x9c>;
			};
		};
	};

	chosen {
		bootargs = "earlycon=uart8250,mmio32,0xff0c0000 swiotlb=1 console=ttyFIQ0 root=PARTUUID=614e0000-0000 rootfstype=squashfs rootwait snd_aloop.index=7 snd_aloop.use_raw_jiffies=1";
	};

	adc-keys {
		compatible = "adc-keys";
		io-channels = <0x8c 0x01>;
		io-channel-names = "buttons";
		poll-interval = <0x64>;
		keyup-threshold-microvolt = <0x1b7740>;

		esc-key {
			linux,code = <0xf8>;
			label = "micmute";
			press-threshold-microvolt = <0x113e10>;
		};

		home-key {
			linux,code = <0x175>;
			label = "mode";
			press-threshold-microvolt = <0xdbf88>;
		};

		menu-key {
			linux,code = <0xcf>;
			label = "play";
			press-threshold-microvolt = <0x98580>;
		};

		vol-down-key {
			linux,code = <0x72>;
			label = "volume down";
			press-threshold-microvolt = <0x493e0>;
		};

		vol-up-key {
			linux,code = <0x73>;
			label = "volume up";
			press-threshold-microvolt = <0x4650>;
		};
	};

	dummy-codec {
		compatible = "rockchip,dummy-codec";
		#sound-dai-cells = <0x00>;
		phandle = <0x92>;
	};

	gpio-keys {
		compatible = "gpio-keys";
		autorepeat;
		pinctrl-names = "default";
		pinctrl-0 = <0x8d>;

		power {
			gpios = <0x1a 0x06 0x01>;
			linux,code = <0x74>;
			label = "GPIO Key Power";
			wakeup-source;
			debounce-interval = <0x64>;
		};
	};

	sdio-pwrseq {
		compatible = "mmc-pwrseq-simple";
		pinctrl-names = "default";
		pinctrl-0 = <0x8e>;
		reset-gpios = <0x1a 0x02 0x01>;
		phandle = <0x7a>;
	};

	acodec-sound {
		compatible = "rockchip,multicodecs-card";
		rockchip,card-name = "rockchip,rk3308-acodec";
		rockchip,codec-hp-det;
		rockchip,mclk-fs = <0x100>;
		rockchip,cpu = <0x8f>;
		rockchip,codec = <0x90>;
		status = "disabled";
		phandle = <0x164>;
	};

	bluetooth-sound {
		status = "okay";
		compatible = "rockchip,multicodecs-card";
		rockchip,card-name = "rockchip,rk3308-pcm";
		rockchip,mclk-fs = <0x80>;
		rockchip,cpu = <0x91>;
		rockchip,codec = <0x92>;
		rockchip,format = "dsp_a";
		rockchip,bitclock-inversion = <0x00>;
		rockchip,wait-card-locked = <0x00>;
		phandle = <0x165>;
	};

	spdif-rx-sound {
		status = "disabled";
		compatible = "simple-audio-card";
		simple-audio-card,name = "rockchip,spdif-rx-sound";
		phandle = <0x166>;

		simple-audio-card,cpu {
			sound-dai = <0x93>;
		};

		simple-audio-card,codec {
			sound-dai = <0x92>;
		};
	};

	spdif-tx-sound {
		status = "disabled";
		compatible = "simple-audio-card";
		simple-audio-card,name = "rockchip,spdif-tx-sound";
		phandle = <0x167>;

		simple-audio-card,cpu {
			sound-dai = <0x94>;
		};

		simple-audio-card,codec {
			sound-dai = <0x92>;
		};
	};

	tas5731-sound {
		status = "disabled";
		compatible = "simple-audio-card";
		simple-audio-card,format = "i2s";
		simple-audio-card,name = "rockchip,tas5731";
		simple-audio-card,mclk-fs = <0x100>;
		phandle = <0x168>;

		simple-audio-card,cpu {
			sound-dai = <0x95>;
		};

		simple-audio-card,codec {
			sound-dai = <0x96>;
		};
	};

	vdd-core {
		compatible = "pwm-regulator";
		pwms = <0x97 0x00 0x1388 0x01>;
		regulator-name = "vdd_core";
		regulator-min-microvolt = <0xc9e78>;
		regulator-max-microvolt = <0x147260>;
		regulator-init-microvolt = <0xf7cd8>;
		regulator-always-on;
		regulator-boot-on;
		regulator-settling-time-up-us = <0xfa>;
		status = "okay";
		phandle = <0x06>;
	};

	vdd-log {
		compatible = "regulator-fixed";
		regulator-name = "vdd_log";
		regulator-always-on;
		regulator-boot-on;
		regulator-min-microvolt = <0x100590>;
		regulator-max-microvolt = <0x100590>;
		phandle = <0x11>;
	};

	vdd-1v0 {
		compatible = "regulator-fixed";
		regulator-name = "vdd_1v0";
		regulator-always-on;
		regulator-boot-on;
		regulator-min-microvolt = <0xf4240>;
		regulator-max-microvolt = <0xf4240>;
		phandle = <0x169>;
	};

	vcc-1v8 {
		compatible = "regulator-fixed";
		regulator-name = "vcc_1v8";
		regulator-always-on;
		regulator-boot-on;
		regulator-min-microvolt = <0x1b7740>;
		regulator-max-microvolt = <0x1b7740>;
		vin-supply = <0x14>;
		phandle = <0x15>;
	};

	vccio-sd {
		compatible = "regulator-gpio";
		regulator-name = "vccio_sd";
		regulator-min-microvolt = <0x1b7740>;
		regulator-max-microvolt = <0x325aa0>;
		gpios = <0x1a 0x0f 0x00>;
		states = <0x1b7740 0x00 0x325aa0 0x01>;
		phandle = <0x16>;
	};

	vcc-sd {
		compatible = "regulator-fixed";
		gpio = <0x98 0x1e 0x01>;
		regulator-name = "vcc_sd";
		regulator-min-microvolt = <0x325aa0>;
		regulator-max-microvolt = <0x325aa0>;
		phandle = <0x76>;
	};

	vcc-1v8-codec {
		compatible = "regulator-fixed";
		regulator-name = "vcc_1v8_codec";
		regulator-always-on;
		regulator-boot-on;
		regulator-min-microvolt = <0x1b7740>;
		regulator-max-microvolt = <0x1b7740>;
		vin-supply = <0x14>;
		phandle = <0x16a>;
	};

	vcc-ddr {
		compatible = "regulator-fixed";
		regulator-name = "vcc_ddr";
		regulator-always-on;
		regulator-boot-on;
		regulator-min-microvolt = <0x16e360>;
		regulator-max-microvolt = <0x16e360>;
		phandle = <0x16b>;
	};

	vcc-io {
		compatible = "regulator-fixed";
		regulator-name = "vcc_io";
		regulator-always-on;
		regulator-boot-on;
		regulator-min-microvolt = <0x325aa0>;
		regulator-max-microvolt = <0x325aa0>;
		phandle = <0x14>;
	};

	vcc-phy-regulator {
		compatible = "regulator-fixed";
		regulator-name = "vcc_phy";
		regulator-always-on;
		regulator-boot-on;
		phandle = <0x7d>;
	};

	vbus-host-regulator {
		compatible = "regulator-fixed";
		enable-active-high;
		gpio = <0x1a 0x15 0x00>;
		pinctrl-names = "default";
		pinctrl-0 = <0x99>;
		regulator-name = "vbus_host";
		phandle = <0x1f>;
	};

	wireless-bluetooth {
		compatible = "bluetooth-platdata";
		uart_rts_gpios = <0x98 0x07 0x01>;
		pinctrl-names = "default\0rts_gpio";
		pinctrl-0 = <0x9a>;
		pinctrl-1 = <0x9b>;
		BT,power_gpio = <0x98 0x0b 0x00>;
		BT,wake_host_irq = <0x98 0x0c 0x00>;
		status = "okay";
	};

	wireless-wlan {
		compatible = "wlan-platdata";
		rockchip,grf = <0x4f>;
		pinctrl-names = "default";
		pinctrl-0 = <0x9c>;
		wifi_chip_type = "ap6255";
		WIFI,host_wake_irq = <0x1a 0x00 0x01>;
		status = "okay";
	};

	i2s-8ch-0-2-dais {
		status = "okay";
		compatible = "rockchip,rk3308-multi-dais\0rockchip,multi-dais";
		dais = <0x6f 0x8f>;
		capture,channel-mapping = <0x06 0x02>;
		playback,channel-mapping = <0x00 0x02>;
		phandle = <0x9d>;
	};

	i2s-dmic-array {
		status = "disabled";
		compatible = "simple-audio-card";
		simple-audio-card,format = "i2s";
		simple-audio-card,name = "rockchip,i2s-dmic-array";
		simple-audio-card,mclk-fs = <0x100>;

		simple-audio-card,cpu {
			sound-dai = <0x6f>;
		};

		simple-audio-card,codec {
			sound-dai = <0x92>;
		};
	};

	vad-sound {
		status = "okay";
		compatible = "rockchip,multicodecs-card";
		rockchip,card-name = "rockchip,rk3308-vad";
		rockchip,cpu = <0x9d>;
		rockchip,codec = <0x90 0x9e>;
	};

	__symbols__ {
		cpu0 = "/cpus/cpu@0";
		cpu1 = "/cpus/cpu@1";
		cpu2 = "/cpus/cpu@2";
		cpu3 = "/cpus/cpu@3";
		CPU_SLEEP = "/cpus/idle-states/cpu-sleep";
		l2 = "/cpus/l2-cache";
		cpu0_opp_table = "/cpu0-opp-table";
		display_subsystem = "/display-subsystem";
		route_rgb = "/display-subsystem/route/route-rgb";
		dmc = "/dmc";
		dmc_opp_table = "/dmc-opp-table";
		fiq_debugger = "/fiq-debugger";
		mac_clkin = "/external-mac-clock";
		ramoops_mem = "/ramoops_mem";
		ramoops = "/ramoops";
		rgb = "/rgb";
		rgb_in_vop = "/rgb/ports/port@0/endpoint@0";
		drm_logo = "/reserved-memory/drm-logo@00000000";
		rockchip_suspend = "/rockchip-suspend";
		xin24m = "/xin24m";
		grf = "/grf@ff000000";
		io_domains = "/grf@ff000000/io-domains";
		pmu_pvtm = "/grf@ff000000/pmu-pvtm";
		detect_grf = "/syscon@ff00b000";
		core_grf = "/syscon@ff00c000";
		pvtm = "/syscon@ff00c000/pvtm";
		i2c0 = "/i2c@ff040000";
		i2c1 = "/i2c@ff050000";
		tas5731 = "/i2c@ff050000/tas5731@1a";
		is31fl3236 = "/i2c@ff050000/led-controller@3c";
		led1 = "/i2c@ff050000/led-controller@3c/led@1";
		led2 = "/i2c@ff050000/led-controller@3c/led@2";
		led3 = "/i2c@ff050000/led-controller@3c/led@3";
		led4 = "/i2c@ff050000/led-controller@3c/led@4";
		led5 = "/i2c@ff050000/led-controller@3c/led@5";
		led6 = "/i2c@ff050000/led-controller@3c/led@6";
		led7 = "/i2c@ff050000/led-controller@3c/led@7";
		led8 = "/i2c@ff050000/led-controller@3c/led@8";
		led9 = "/i2c@ff050000/led-controller@3c/led@9";
		led10 = "/i2c@ff050000/led-controller@3c/led@10";
		led11 = "/i2c@ff050000/led-controller@3c/led@11";
		led12 = "/i2c@ff050000/led-controller@3c/led@12";
		led13 = "/i2c@ff050000/led-controller@3c/led@13";
		led14 = "/i2c@ff050000/led-controller@3c/led@14";
		led15 = "/i2c@ff050000/led-controller@3c/led@15";
		led16 = "/i2c@ff050000/led-controller@3c/led@16";
		led17 = "/i2c@ff050000/led-controller@3c/led@17";
		led18 = "/i2c@ff050000/led-controller@3c/led@18";
		led19 = "/i2c@ff050000/led-controller@3c/led@19";
		led20 = "/i2c@ff050000/led-controller@3c/led@20";
		led21 = "/i2c@ff050000/led-controller@3c/led@21";
		led22 = "/i2c@ff050000/led-controller@3c/led@22";
		led23 = "/i2c@ff050000/led-controller@3c/led@23";
		led124 = "/i2c@ff050000/led-controller@3c/led@24";
		led25 = "/i2c@ff050000/led-controller@3c/led@25";
		led26 = "/i2c@ff050000/led-controller@3c/led@26";
		led27 = "/i2c@ff050000/led-controller@3c/led@27";
		led28 = "/i2c@ff050000/led-controller@3c/led@28";
		led29 = "/i2c@ff050000/led-controller@3c/led@29";
		led30 = "/i2c@ff050000/led-controller@3c/led@30";
		led31 = "/i2c@ff050000/led-controller@3c/led@31";
		led32 = "/i2c@ff050000/led-controller@3c/led@32";
		led33 = "/i2c@ff050000/led-controller@3c/led@33";
		led34 = "/i2c@ff050000/led-controller@3c/led@34";
		led35 = "/i2c@ff050000/led-controller@3c/led@35";
		led36 = "/i2c@ff050000/led-controller@3c/led@36";
		i2c2 = "/i2c@ff060000";
		i2c3 = "/i2c@ff070000";
		usb2phy_grf = "/syscon@ff008000";
		u2phy = "/syscon@ff008000/usb2-phy@100";
		u2phy_otg = "/syscon@ff008000/usb2-phy@100/otg-port";
		u2phy_host = "/syscon@ff008000/usb2-phy@100/host-port";
		wdt = "/watchdog@ff080000";
		uart0 = "/serial@ff0a0000";
		uart1 = "/serial@ff0b0000";
		uart2 = "/serial@ff0c0000";
		uart3 = "/serial@ff0d0000";
		uart4 = "/serial@ff0e0000";
		spi0 = "/spi@ff120000";
		spi1 = "/spi@ff130000";
		spi2 = "/spi@ff140000";
		pwm8 = "/pwm@ff160000";
		pwm9 = "/pwm@ff160010";
		pwm10 = "/pwm@ff160020";
		pwm11 = "/pwm@ff160030";
		pwm4 = "/pwm@ff170000";
		pwm5 = "/pwm@ff170010";
		pwm6 = "/pwm@ff170020";
		pwm7 = "/pwm@ff170030";
		pwm0 = "/pwm@ff180000";
		pwm1 = "/pwm@ff180010";
		pwm2 = "/pwm@ff180020";
		pwm3 = "/pwm@ff180030";
		rktimer = "/rktimer@ff1a0000";
		rk_timer_rtc = "/rk-timer-rtc@ff1a0020";
		saradc = "/saradc@ff1e0000";
		thermal_zones = "/thermal-zones";
		soc_thermal = "/thermal-zones/soc-thermal";
		threshold = "/thermal-zones/soc-thermal/trips/trip-point-0";
		target = "/thermal-zones/soc-thermal/trips/trip-point-1";
		soc_crit = "/thermal-zones/soc-thermal/trips/soc-crit";
		logic_thermal = "/thermal-zones/logic-thermal";
		tsadc = "/tsadc@ff1f0000";
		otp = "/otp@ff210000";
		otp_id = "/otp@ff210000/id@7";
		cpu_leakage = "/otp@ff210000/cpu-leakage@17";
		logic_leakage = "/otp@ff210000/logic-leakage@18";
		dmac0 = "/amba/dma-controller@ff2c0000";
		dmac1 = "/amba/dma-controller@ff2d0000";
		vop = "/vop@ff2e0000";
		vop_out = "/vop@ff2e0000/port";
		vop_out_rgb = "/vop@ff2e0000/port/endpoint@0";
		rng = "/rng@ff2f0000";
		i2s_8ch_0 = "/i2s@ff300000";
		i2s_8ch_1 = "/i2s@ff310000";
		i2s_8ch_2 = "/i2s@ff320000";
		i2s_8ch_3 = "/i2s@ff330000";
		i2s_2ch_0 = "/i2s@ff350000";
		i2s_2ch_1 = "/i2s@ff360000";
		pdm_8ch = "/pdm@ff380000";
		spdif_tx = "/spdif-tx@ff3a0000";
		spdif_rx = "/spdif-rx@ff3b0000";
		vad = "/vad@ff3c0000";
		usb20_otg = "/usb@ff400000";
		usb_host0_ehci = "/usb@ff440000";
		usb_host0_ohci = "/usb@ff450000";
		sdmmc = "/dwmmc@ff480000";
		emmc = "/dwmmc@ff490000";
		sdio = "/dwmmc@ff4a0000";
		nandc = "/nandc@ff4b0000";
		sfc = "/sfc@ff4c0000";
		mac = "/ethernet@ff4e0000";
		cru = "/clock-controller@ff500000";
		cpu_boost = "/cpu-boost@ff550000";
		acodec = "/acodec@ff560000";
		gic = "/interrupt-controller@ff580000";
		sram = "/sram@fff80000";
		vad_sram = "/sram@fff80000/vad-sram@8000";
		rockchip_system_monitor = "/rockchip-system-monitor";
		pinctrl = "/pinctrl";
		gpio0 = "/pinctrl/gpio0@ff220000";
		gpio1 = "/pinctrl/gpio1@ff230000";
		gpio2 = "/pinctrl/gpio2@ff240000";
		gpio3 = "/pinctrl/gpio3@ff250000";
		gpio4 = "/pinctrl/gpio4@ff260000";
		pcfg_pull_up = "/pinctrl/pcfg-pull-up";
		pcfg_pull_down = "/pinctrl/pcfg-pull-down";
		pcfg_pull_none = "/pinctrl/pcfg-pull-none";
		pcfg_pull_none_2ma = "/pinctrl/pcfg-pull-none-2ma";
		pcfg_pull_up_2ma = "/pinctrl/pcfg-pull-up-2ma";
		pcfg_pull_up_4ma = "/pinctrl/pcfg-pull-up-4ma";
		pcfg_pull_none_4ma = "/pinctrl/pcfg-pull-none-4ma";
		pcfg_pull_down_4ma = "/pinctrl/pcfg-pull-down-4ma";
		pcfg_pull_none_8ma = "/pinctrl/pcfg-pull-none-8ma";
		pcfg_pull_up_8ma = "/pinctrl/pcfg-pull-up-8ma";
		pcfg_pull_none_12ma = "/pinctrl/pcfg-pull-none-12ma";
		pcfg_pull_up_12ma = "/pinctrl/pcfg-pull-up-12ma";
		pcfg_pull_none_smt = "/pinctrl/pcfg-pull-none-smt";
		pcfg_output_high = "/pinctrl/pcfg-output-high";
		pcfg_output_low = "/pinctrl/pcfg-output-low";
		pcfg_input_high = "/pinctrl/pcfg-input-high";
		pcfg_input = "/pinctrl/pcfg-input";
		ext_micbias_en = "/pinctrl/ext_micbias/ext-micbias-en";
		i2c0_xfer = "/pinctrl/i2c0/i2c0-xfer";
		i2c1_xfer = "/pinctrl/i2c1/i2c1-xfer";
		i2c2_xfer = "/pinctrl/i2c2/i2c2-xfer";
		i2c3m0_xfer = "/pinctrl/i2c3-m0/i2c3m0-xfer";
		i2c3m1_xfer = "/pinctrl/i2c3-m1/i2c3m1-xfer";
		i2c3m2_xfer = "/pinctrl/i2c3-m2/i2c3m2-xfer";
		i2s_2ch_0_mclk = "/pinctrl/i2s_2ch_0/i2s-2ch-0-mclk";
		i2s_2ch_0_sclk = "/pinctrl/i2s_2ch_0/i2s-2ch-0-sclk";
		i2s_2ch_0_lrck = "/pinctrl/i2s_2ch_0/i2s-2ch-0-lrck";
		i2s_2ch_0_sdo = "/pinctrl/i2s_2ch_0/i2s-2ch-0-sdo";
		i2s_2ch_0_sdi = "/pinctrl/i2s_2ch_0/i2s-2ch-0-sdi";
		i2s_8ch_0_mclk = "/pinctrl/i2s_8ch_0/i2s-8ch-0-mclk";
		i2s_8ch_0_sclktx = "/pinctrl/i2s_8ch_0/i2s-8ch-0-sclktx";
		i2s_8ch_0_sclkrx = "/pinctrl/i2s_8ch_0/i2s-8ch-0-sclkrx";
		i2s_8ch_0_lrcktx = "/pinctrl/i2s_8ch_0/i2s-8ch-0-lrcktx";
		i2s_8ch_0_lrckrx = "/pinctrl/i2s_8ch_0/i2s-8ch-0-lrckrx";
		i2s_8ch_0_sdo0 = "/pinctrl/i2s_8ch_0/i2s-8ch-0-sdo0";
		i2s_8ch_0_sdo1 = "/pinctrl/i2s_8ch_0/i2s-8ch-0-sdo1";
		i2s_8ch_0_sdo2 = "/pinctrl/i2s_8ch_0/i2s-8ch-0-sdo2";
		i2s_8ch_0_sdo3 = "/pinctrl/i2s_8ch_0/i2s-8ch-0-sdo3";
		i2s_8ch_0_sdi0 = "/pinctrl/i2s_8ch_0/i2s-8ch-0-sdi0";
		i2s_8ch_0_sdi1 = "/pinctrl/i2s_8ch_0/i2s-8ch-0-sdi1";
		i2s_8ch_0_sdi2 = "/pinctrl/i2s_8ch_0/i2s-8ch-0-sdi2";
		i2s_8ch_0_sdi3 = "/pinctrl/i2s_8ch_0/i2s-8ch-0-sdi3";
		i2s_8ch_1_m0_mclk = "/pinctrl/i2s_8ch_1_m0/i2s-8ch-1-m0-mclk";
		i2s_8ch_1_m0_sclktx = "/pinctrl/i2s_8ch_1_m0/i2s-8ch-1-m0-sclktx";
		i2s_8ch_1_m0_sclkrx = "/pinctrl/i2s_8ch_1_m0/i2s-8ch-1-m0-sclkrx";
		i2s_8ch_1_m0_lrcktx = "/pinctrl/i2s_8ch_1_m0/i2s-8ch-1-m0-lrcktx";
		i2s_8ch_1_m0_lrckrx = "/pinctrl/i2s_8ch_1_m0/i2s-8ch-1-m0-lrckrx";
		i2s_8ch_1_m0_sdo0 = "/pinctrl/i2s_8ch_1_m0/i2s-8ch-1-m0-sdo0";
		i2s_8ch_1_m0_sdo1_sdi3 = "/pinctrl/i2s_8ch_1_m0/i2s-8ch-1-m0-sdo1-sdi3";
		i2s_8ch_1_m0_sdo2_sdi2 = "/pinctrl/i2s_8ch_1_m0/i2s-8ch-1-m0-sdo2-sdi2";
		i2s_8ch_1_m0_sdo3_sdi1 = "/pinctrl/i2s_8ch_1_m0/i2s-8ch-1-m0-sdo3_sdi1";
		i2s_8ch_1_m0_sdi0 = "/pinctrl/i2s_8ch_1_m0/i2s-8ch-1-m0-sdi0";
		i2s_8ch_1_m1_mclk = "/pinctrl/i2s_8ch_1_m1/i2s-8ch-1-m1-mclk";
		i2s_8ch_1_m1_sclktx = "/pinctrl/i2s_8ch_1_m1/i2s-8ch-1-m1-sclktx";
		i2s_8ch_1_m1_sclkrx = "/pinctrl/i2s_8ch_1_m1/i2s-8ch-1-m1-sclkrx";
		i2s_8ch_1_m1_lrcktx = "/pinctrl/i2s_8ch_1_m1/i2s-8ch-1-m1-lrcktx";
		i2s_8ch_1_m1_lrckrx = "/pinctrl/i2s_8ch_1_m1/i2s-8ch-1-m1-lrckrx";
		i2s_8ch_1_m1_sdo0 = "/pinctrl/i2s_8ch_1_m1/i2s-8ch-1-m1-sdo0";
		i2s_8ch_1_m1_sdo1_sdi3 = "/pinctrl/i2s_8ch_1_m1/i2s-8ch-1-m1-sdo1-sdi3";
		i2s_8ch_1_m1_sdo2_sdi2 = "/pinctrl/i2s_8ch_1_m1/i2s-8ch-1-m1-sdo2-sdi2";
		i2s_8ch_1_m1_sdo3_sdi1 = "/pinctrl/i2s_8ch_1_m1/i2s-8ch-1-m1-sdo3_sdi1";
		i2s_8ch_1_m1_sdi0 = "/pinctrl/i2s_8ch_1_m1/i2s-8ch-1-m1-sdi0";
		lcdc_ctl = "/pinctrl/lcdc/lcdc-ctl";
		lcdc_rgb888_m0 = "/pinctrl/lcdc/lcdc-rgb888-m0";
		lcdc_rgb888_m1 = "/pinctrl/lcdc/lcdc-rgb888-m1";
		pdm_m0_clk = "/pinctrl/pdm_m0/pdm-m0-clk";
		pdm_m0_sdi0 = "/pinctrl/pdm_m0/pdm-m0-sdi0";
		pdm_m0_sdi1 = "/pinctrl/pdm_m0/pdm-m0-sdi1";
		pdm_m0_sdi2 = "/pinctrl/pdm_m0/pdm-m0-sdi2";
		pdm_m0_sdi3 = "/pinctrl/pdm_m0/pdm-m0-sdi3";
		pdm_m1_clk = "/pinctrl/pdm_m1/pdm-m1-clk";
		pdm_m1_sdi0 = "/pinctrl/pdm_m1/pdm-m1-sdi0";
		pdm_m1_sdi1 = "/pinctrl/pdm_m1/pdm-m1-sdi1";
		pdm_m1_sdi2 = "/pinctrl/pdm_m1/pdm-m1-sdi2";
		pdm_m1_sdi3 = "/pinctrl/pdm_m1/pdm-m1-sdi3";
		pdm_m2_clkm = "/pinctrl/pdm_m2/pdm-m2-clkm";
		pdm_m2_clk = "/pinctrl/pdm_m2/pdm-m2-clk";
		pdm_m2_sdi0 = "/pinctrl/pdm_m2/pdm-m2-sdi0";
		pdm_m2_sdi1 = "/pinctrl/pdm_m2/pdm-m2-sdi1";
		pdm_m2_sdi2 = "/pinctrl/pdm_m2/pdm-m2-sdi2";
		pdm_m2_sdi3 = "/pinctrl/pdm_m2/pdm-m2-sdi3";
		spdif_in = "/pinctrl/spdif_in/spdif-in";
		spdif_out = "/pinctrl/spdif_out/spdif-out";
		tsadc_otp_gpio = "/pinctrl/tsadc/tsadc-otp-gpio";
		tsadc_otp_out = "/pinctrl/tsadc/tsadc-otp-out";
		uart0_xfer = "/pinctrl/uart0/uart0-xfer";
		uart0_cts = "/pinctrl/uart0/uart0-cts";
		uart0_rts = "/pinctrl/uart0/uart0-rts";
		uart0_rts_gpio = "/pinctrl/uart0/uart0-rts-gpio";
		uart1_xfer = "/pinctrl/uart1/uart1-xfer";
		uart1_cts = "/pinctrl/uart1/uart1-cts";
		uart1_rts = "/pinctrl/uart1/uart1-rts";
		uart2m0_xfer = "/pinctrl/uart2-m0/uart2m0-xfer";
		uart2m1_xfer = "/pinctrl/uart2-m1/uart2m1-xfer";
		uart3_xfer = "/pinctrl/uart3/uart3-xfer";
		uart3m1_xfer = "/pinctrl/uart3-m1/uart3m1-xfer";
		uart4_xfer = "/pinctrl/uart4/uart4-xfer";
		uart4_cts = "/pinctrl/uart4/uart4-cts";
		uart4_rts = "/pinctrl/uart4/uart4-rts";
		uart4_rts_gpio = "/pinctrl/uart4/uart4-rts-gpio";
		spi0_clk = "/pinctrl/spi0/spi0-clk";
		spi0_csn0 = "/pinctrl/spi0/spi0-csn0";
		spi0_miso = "/pinctrl/spi0/spi0-miso";
		spi0_mosi = "/pinctrl/spi0/spi0-mosi";
		spi0_clk_hs = "/pinctrl/spi0/spi0-clk-hs";
		spi0_miso_hs = "/pinctrl/spi0/spi0-miso-hs";
		spi0_mosi_hs = "/pinctrl/spi0/spi0-mosi-hs";
		spi1_clk = "/pinctrl/spi1/spi1-clk";
		spi1_csn0 = "/pinctrl/spi1/spi1-csn0";
		spi1_miso = "/pinctrl/spi1/spi1-miso";
		spi1_mosi = "/pinctrl/spi1/spi1-mosi";
		spi1_clk_hs = "/pinctrl/spi1/spi1-clk-hs";
		spi1_miso_hs = "/pinctrl/spi1/spi1-miso-hs";
		spi1_mosi_hs = "/pinctrl/spi1/spi1-mosi-hs";
		spi1m1_miso = "/pinctrl/spi1-m1/spi1m1-miso";
		spi1m1_mosi = "/pinctrl/spi1-m1/spi1m1-mosi";
		spi1m1_clk = "/pinctrl/spi1-m1/spi1m1-clk";
		spi1m1_csn0 = "/pinctrl/spi1-m1/spi1m1-csn0";
		spi1m1_miso_hs = "/pinctrl/spi1-m1/spi1m1-miso-hs";
		spi1m1_mosi_hs = "/pinctrl/spi1-m1/spi1m1-mosi-hs";
		spi1m1_clk_hs = "/pinctrl/spi1-m1/spi1m1-clk-hs";
		spi1m1_csn0_hs = "/pinctrl/spi1-m1/spi1m1-csn0-hs";
		spi2_clk = "/pinctrl/spi2/spi2-clk";
		spi2_csn0 = "/pinctrl/spi2/spi2-csn0";
		spi2_miso = "/pinctrl/spi2/spi2-miso";
		spi2_mosi = "/pinctrl/spi2/spi2-mosi";
		spi2_clk_hs = "/pinctrl/spi2/spi2-clk-hs";
		spi2_miso_hs = "/pinctrl/spi2/spi2-miso-hs";
		spi2_mosi_hs = "/pinctrl/spi2/spi2-mosi-hs";
		sdmmc_clk = "/pinctrl/sdmmc/sdmmc-clk";
		sdmmc_cmd = "/pinctrl/sdmmc/sdmmc-cmd";
		sdmmc_det = "/pinctrl/sdmmc/sdmmc-det";
		sdmmc_pwren = "/pinctrl/sdmmc/sdmmc-pwren";
		sdmmc_bus1 = "/pinctrl/sdmmc/sdmmc-bus1";
		sdmmc_bus4 = "/pinctrl/sdmmc/sdmmc-bus4";
		sdmmc_gpio = "/pinctrl/sdmmc/sdmmc-gpio";
		sdio_clk = "/pinctrl/sdio/sdio-clk";
		sdio_cmd = "/pinctrl/sdio/sdio-cmd";
		sdio_pwren = "/pinctrl/sdio/sdio-pwren";
		sdio_wrpt = "/pinctrl/sdio/sdio-wrpt";
		sdio_intn = "/pinctrl/sdio/sdio-intn";
		sdio_bus1 = "/pinctrl/sdio/sdio-bus1";
		sdio_bus4 = "/pinctrl/sdio/sdio-bus4";
		sdio_gpio = "/pinctrl/sdio/sdio-gpio";
		emmc_clk = "/pinctrl/emmc/emmc-clk";
		emmc_cmd = "/pinctrl/emmc/emmc-cmd";
		emmc_pwren = "/pinctrl/emmc/emmc-pwren";
		emmc_rstn = "/pinctrl/emmc/emmc-rstn";
		emmc_bus1 = "/pinctrl/emmc/emmc-bus1";
		emmc_bus4 = "/pinctrl/emmc/emmc-bus4";
		emmc_bus8 = "/pinctrl/emmc/emmc-bus8";
		flash_csn0 = "/pinctrl/flash/flash-csn0";
		flash_rdy = "/pinctrl/flash/flash-rdy";
		flash_ale = "/pinctrl/flash/flash-ale";
		flash_cle = "/pinctrl/flash/flash-cle";
		flash_wrn = "/pinctrl/flash/flash-wrn";
		flash_rdn = "/pinctrl/flash/flash-rdn";
		flash_bus8 = "/pinctrl/flash/flash-bus8";
		pwm0_pin = "/pinctrl/pwm0/pwm0-pin";
		pwm0_pin_pull_down = "/pinctrl/pwm0/pwm0-pin-pull-down";
		pwm1_pin = "/pinctrl/pwm1/pwm1-pin";
		pwm1_pin_pull_down = "/pinctrl/pwm1/pwm1-pin-pull-down";
		pwm2_pin = "/pinctrl/pwm2/pwm2-pin";
		pwm2_pin_pull_down = "/pinctrl/pwm2/pwm2-pin-pull-down";
		pwm3_pin = "/pinctrl/pwm3/pwm3-pin";
		pwm3_pin_pull_down = "/pinctrl/pwm3/pwm3-pin-pull-down";
		pwm4_pin = "/pinctrl/pwm4/pwm4-pin";
		pwm4_pin_pull_down = "/pinctrl/pwm4/pwm4-pin-pull-down";
		pwm5_pin = "/pinctrl/pwm5/pwm5-pin";
		pwm5_pin_pull_down = "/pinctrl/pwm5/pwm5-pin-pull-down";
		pwm6_pin = "/pinctrl/pwm6/pwm6-pin";
		pwm6_pin_pull_down = "/pinctrl/pwm6/pwm6-pin-pull-down";
		pwm7_pin = "/pinctrl/pwm7/pwm7-pin";
		pwm7_pin_pull_down = "/pinctrl/pwm7/pwm7-pin-pull-down";
		pwm8_pin = "/pinctrl/pwm8/pwm8-pin";
		pwm8_pin_pull_down = "/pinctrl/pwm8/pwm8-pin-pull-down";
		pwm9_pin = "/pinctrl/pwm9/pwm9-pin";
		pwm9_pin_pull_down = "/pinctrl/pwm9/pwm9-pin-pull-down";
		pwm10_pin = "/pinctrl/pwm10/pwm10-pin";
		pwm10_pin_pull_down = "/pinctrl/pwm10/pwm10-pin-pull-down";
		pwm11_pin = "/pinctrl/pwm11/pwm11-pin";
		pwm11_pin_pull_down = "/pinctrl/pwm11/pwm11-pin-pull-down";
		rmii_pins = "/pinctrl/gmac/rmii-pins";
		mac_refclk_12ma = "/pinctrl/gmac/mac-refclk-12ma";
		mac_refclk = "/pinctrl/gmac/mac-refclk";
		rmiim1_pins = "/pinctrl/gmac-m1/rmiim1-pins";
		macm1_refclk_12ma = "/pinctrl/gmac-m1/macm1-refclk-12ma";
		macm1_refclk = "/pinctrl/gmac-m1/macm1-refclk";
		rtc_32k = "/pinctrl/rtc/rtc-32k";
		canm0_pins = "/pinctrl/can-m0/canm0-pins";
		canm1_pins = "/pinctrl/can-m1/canm1-pins";
		canm2_pins = "/pinctrl/can-m2/canm2-pins";
		owirem0_pins = "/pinctrl/owire-m0/owirem0-pins";
		owirem1_pins = "/pinctrl/owire-m1/owirem1-pins";
		owirem2_pins = "/pinctrl/owire-m2/owirem2-pins";
		pwr_key = "/pinctrl/buttons/pwr-key";
		usb_drv = "/pinctrl/usb/usb-drv";
		wifi_enable_h = "/pinctrl/sdio-pwrseq/wifi-enable-h";
		wifi_wake_host = "/pinctrl/wireless-wlan/wifi-wake-host";
		dummy_codec = "/dummy-codec";
		sdio_pwrseq = "/sdio-pwrseq";
		acodec_sound = "/acodec-sound";
		bluetooth_sound = "/bluetooth-sound";
		spdif_rx_sound = "/spdif-rx-sound";
		spdif_tx_sound = "/spdif-tx-sound";
		tas5731_sound = "/tas5731-sound";
		vdd_core = "/vdd-core";
		vdd_log = "/vdd-log";
		vdd_1v0 = "/vdd-1v0";
		vccio_sdio = "/vcc-1v8";
		vcc_1v8 = "/vcc-1v8";
		vccio_sd = "/vccio-sd";
		vcc_sd = "/vcc-sd";
		vcc_1v8_codec = "/vcc-1v8-codec";
		vcc_ddr = "/vcc-ddr";
		vcc_3v3_codec = "/vcc-io";
		vcc_io = "/vcc-io";
		vcc_phy = "/vcc-phy-regulator";
		vbus_host = "/vbus-host-regulator";
		i2s_8ch_0_2_dais = "/i2s-8ch-0-2-dais";
	};
};
